[part 11 of 11: package /COM/VECTOR/CFG/WORKFLOW/SYSDESC/SYNC]
AUTOSAR XML (schema 00053)
package /COM/VECTOR/CFG/WORKFLOW/SYSDESC/SYNC  (continued)
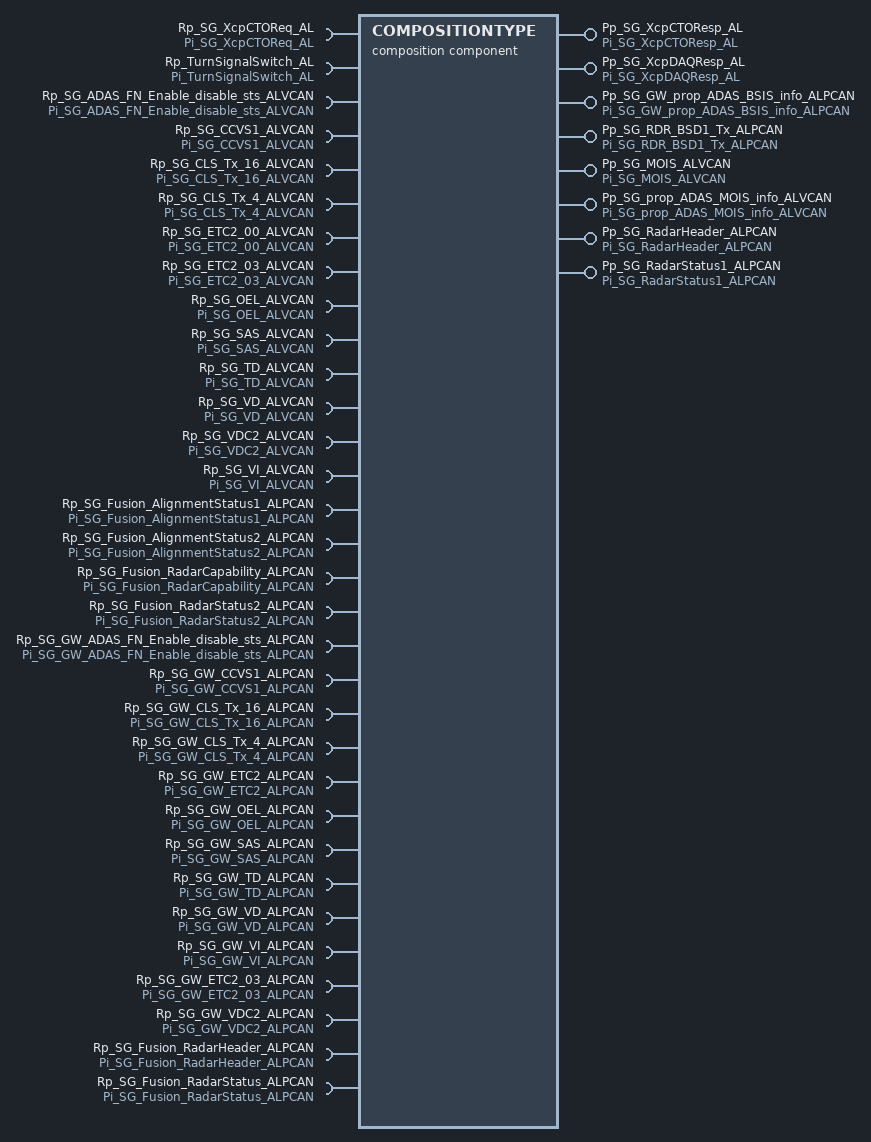
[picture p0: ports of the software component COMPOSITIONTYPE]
  composition sw component type COMPOSITIONTYPE  (continued)
    require port Rp_SG_XcpCTOReq_AL: nonqueued-receiver-com-spec{data-element=Vdp_SG_XcpCTOReq_AL, init-value=fields=[STS_PID:0, STS_XCP_REQ_CTO_Byte1:0, STS_XCP_REQ_CTO_Byte2:0, STS_XCP_REQ_CTO_Byte3:0, STS_XCP_REQ_CTO_Byte4:0, STS_XCP_REQ_CTO_Byte5:0, STS_XCP_REQ_CTO_Byte6:0, STS_XCP_REQ_CTO_Byte7:0, STS_XCP_REQ_CTO_Byte8:0, STS_XCP_REQ_CTO_Byte9:0, STS_XCP_REQ_CTO_Byte10:0, STS_XCP_REQ_CTO_Byte11:0, STS_XCP_REQ_CTO_Byte12:0, STS_XCP_REQ_CTO_Byte13:0, STS_XCP_REQ_CTO_Byte14:0, STS_XCP_REQ_CTO_Byte15:0, STS_XCP_REQ_CTO_Byte16:0, STS_XCP_REQ_CTO_Byte17:0, STS_XCP_REQ_CTO_Byte18:0, STS_XCP_REQ_CTO_Byte19:0, STS_XCP_REQ_CTO_Byte20:0, STS_XCP_REQ_CTO_Byte21:0, STS_XCP_REQ_CTO_Byte22:0, STS_XCP_REQ_CTO_Byte23:0, STS_XCP_REQ_CTO_Byte24:0, STS_XCP_REQ_CTO_Byte25:0, STS_XCP_REQ_CTO_Byte26:0, STS_XCP_REQ_CTO_Byte27:0, STS_XCP_REQ_CTO_Byte28:0, STS_XCP_REQ_CTO_Byte29:0, STS_XCP_REQ_CTO_Byte30:0, STS_XCP_REQ_CTO_Byte31:0, STS_XCP_REQ_CTO_Byte32:0, STS_XCP_REQ_CTO_Byte33:0, STS_XCP_REQ_CTO_Byte34:0, STS_XCP_REQ_CTO_Byte35:0, STS_XCP_REQ_CTO_Byte36:0, STS_XCP_REQ_CTO_Byte37:0, STS_XCP_REQ_CTO_Byte38:0, STS_XCP_REQ_CTO_Byte39:0, STS_XCP_REQ_CTO_Byte40:0, STS_XCP_REQ_CTO_Byte41:0, STS_XCP_REQ_CTO_Byte42:0, STS_XCP_REQ_CTO_Byte43:0, STS_XCP_REQ_CTO_Byte44:0, STS_XCP_REQ_CTO_Byte45:0, STS_XCP_REQ_CTO_Byte46:0, STS_XCP_REQ_CTO_Byte47:0, STS_XCP_REQ_CTO_Byte48:0, STS_XCP_REQ_CTO_Byte49:0, STS_XCP_REQ_CTO_Byte50:0, STS_XCP_REQ_CTO_Byte51:0, STS_XCP_REQ_CTO_Byte52:0, STS_XCP_REQ_CTO_Byte53:0, STS_XCP_REQ_CTO_Byte54:0, STS_XCP_REQ_CTO_Byte55:0, STS_XCP_REQ_CTO_Byte56:0, STS_XCP_REQ_CTO_Byte57:0, STS_XCP_REQ_CTO_Byte58:0, STS_XCP_REQ_CTO_Byte59:0, STS_XCP_REQ_CTO_Byte60:0, STS_XCP_REQ_CTO_Byte61:0, STS_XCP_REQ_CTO_Byte62:0, STS_XCP_REQ_CTO_Byte63:0]}, required-interface=Pi_SG_XcpCTOReq_AL
    provide port Pp_SG_XcpCTOResp_AL: nonqueued-sender-com-spec{data-element=Vdp_SG_XcpCTOResp_AL, init-value=fields=[STS_XCP_RES_CTO_Byte0:0, STS_XCP_RES_CTO_Byte1:0, STS_XCP_RES_CTO_Byte2:0, STS_XCP_RES_CTO_Byte3:0, STS_XCP_RES_CTO_Byte4:0, STS_XCP_RES_CTO_Byte5:0, STS_XCP_RES_CTO_Byte6:0, STS_XCP_RES_CTO_Byte7:0, STS_XCP_RES_CTO_Byte8:0, STS_XCP_RES_CTO_Byte9:0, STS_XCP_RES_CTO_Byte10:0, STS_XCP_RES_CTO_Byte11:0, STS_XCP_RES_CTO_Byte12:0, STS_XCP_RES_CTO_Byte13:0, STS_XCP_RES_CTO_Byte14:0, STS_XCP_RES_CTO_Byte15:0, STS_XCP_RES_CTO_Byte16:0, STS_XCP_RES_CTO_Byte17:0, STS_XCP_RES_CTO_Byte18:0, STS_XCP_RES_CTO_Byte19:0, STS_XCP_RES_CTO_Byte20:0, STS_XCP_RES_CTO_Byte21:0, STS_XCP_RES_CTO_Byte22:0, STS_XCP_RES_CTO_Byte23:0, STS_XCP_RES_CTO_Byte24:0, STS_XCP_RES_CTO_Byte25:0, STS_XCP_RES_CTO_Byte26:0, STS_XCP_RES_CTO_Byte27:0, STS_XCP_RES_CTO_Byte28:0, STS_XCP_RES_CTO_Byte29:0, STS_XCP_RES_CTO_Byte30:0, STS_XCP_RES_CTO_Byte31:0, STS_XCP_RES_CTO_Byte32:0, STS_XCP_RES_CTO_Byte33:0, STS_XCP_RES_CTO_Byte34:0, STS_XCP_RES_CTO_Byte35:0, STS_XCP_RES_CTO_Byte36:0, STS_XCP_RES_CTO_Byte37:0, STS_XCP_RES_CTO_Byte38:0, STS_XCP_RES_CTO_Byte39:0, STS_XCP_RES_CTO_Byte40:0, STS_XCP_RES_CTO_Byte41:0, STS_XCP_RES_CTO_Byte42:0, STS_XCP_RES_CTO_Byte43:0, STS_XCP_RES_CTO_Byte44:0, STS_XCP_RES_CTO_Byte45:0, STS_XCP_RES_CTO_Byte46:0, STS_XCP_RES_CTO_Byte47:0, STS_XCP_RES_CTO_Byte48:0, STS_XCP_RES_CTO_Byte49:0, STS_XCP_RES_CTO_Byte50:0, STS_XCP_RES_CTO_Byte51:0, STS_XCP_RES_CTO_Byte52:0, STS_XCP_RES_CTO_Byte53:0, STS_XCP_RES_CTO_Byte54:0, STS_XCP_RES_CTO_Byte55:0, STS_XCP_RES_CTO_Byte56:0, STS_XCP_RES_CTO_Byte57:0, STS_XCP_RES_CTO_Byte58:0, STS_XCP_RES_CTO_Byte59:0, STS_XCP_RES_CTO_Byte60:0, STS_XCP_RES_CTO_Byte61:0, STS_XCP_RES_CTO_Byte62:0, STS_XCP_RES_CTO_Byte63:0]}, provided-interface=Pi_SG_XcpCTOResp_AL
    provide port Pp_SG_XcpDAQResp_AL: nonqueued-sender-com-spec{data-element=Vdp_SG_XcpDAQResp_AL, init-value=fields=[STS_XCP_RES_DAQ_Byte0:0, STS_XCP_RES_DAQ_Byte1:0, STS_XCP_RES_DAQ_Byte2:0, STS_XCP_RES_DAQ_Byte3:0, STS_XCP_RES_DAQ_Byte4:0, STS_XCP_RES_DAQ_Byte5:0, STS_XCP_RES_DAQ_Byte6:0, STS_XCP_RES_DAQ_Byte7:0, STS_XCP_RES_DAQ_Byte8:0, STS_XCP_RES_DAQ_Byte9:0, STS_XCP_RES_DAQ_Byte10:0, STS_XCP_RES_DAQ_Byte11:0, STS_XCP_RES_DAQ_Byte12:0, STS_XCP_RES_DAQ_Byte13:0, STS_XCP_RES_DAQ_Byte14:0, STS_XCP_RES_DAQ_Byte15:0, STS_XCP_RES_DAQ_Byte16:0, STS_XCP_RES_DAQ_Byte17:0, STS_XCP_RES_DAQ_Byte18:0, STS_XCP_RES_DAQ_Byte19:0, STS_XCP_RES_DAQ_Byte20:0, STS_XCP_RES_DAQ_Byte21:0, STS_XCP_RES_DAQ_Byte22:0, STS_XCP_RES_DAQ_Byte23:0, STS_XCP_RES_DAQ_Byte24:0, STS_XCP_RES_DAQ_Byte25:0, STS_XCP_RES_DAQ_Byte26:0, STS_XCP_RES_DAQ_Byte27:0, STS_XCP_RES_DAQ_Byte28:0, STS_XCP_RES_DAQ_Byte29:0, STS_XCP_RES_DAQ_Byte30:0, STS_XCP_RES_DAQ_Byte31:0, STS_XCP_RES_DAQ_Byte32:0, STS_XCP_RES_DAQ_Byte33:0, STS_XCP_RES_DAQ_Byte34:0, STS_XCP_RES_DAQ_Byte35:0, STS_XCP_RES_DAQ_Byte36:0, STS_XCP_RES_DAQ_Byte37:0, STS_XCP_RES_DAQ_Byte38:0, STS_XCP_RES_DAQ_Byte39:0, STS_XCP_RES_DAQ_Byte40:0, STS_XCP_RES_DAQ_Byte41:0, STS_XCP_RES_DAQ_Byte42:0, STS_XCP_RES_DAQ_Byte43:0, STS_XCP_RES_DAQ_Byte44:0, STS_XCP_RES_DAQ_Byte45:0, STS_XCP_RES_DAQ_Byte46:0, STS_XCP_RES_DAQ_Byte47:0, STS_XCP_RES_DAQ_Byte48:0, STS_XCP_RES_DAQ_Byte49:0, STS_XCP_RES_DAQ_Byte50:0, STS_XCP_RES_DAQ_Byte51:0, STS_XCP_RES_DAQ_Byte52:0, STS_XCP_RES_DAQ_Byte53:0, STS_XCP_RES_DAQ_Byte54:0, STS_XCP_RES_DAQ_Byte55:0, STS_XCP_RES_DAQ_Byte56:0, STS_XCP_RES_DAQ_Byte57:0, STS_XCP_RES_DAQ_Byte58:0, STS_XCP_RES_DAQ_Byte59:0, STS_XCP_RES_DAQ_Byte60:0, STS_XCP_RES_DAQ_Byte61:0, STS_XCP_RES_DAQ_Byte62:0, STS_XCP_RES_DAQ_Byte63:0]}, provided-interface=Pi_SG_XcpDAQResp_AL
    29 x require port:
      Rp_TurnSignalSwitch_AL: nonqueued-receiver-com-spec{data-element=Vdp_TurnSignalSwitch_AL, init-value=0}, required-interface=Pi_TurnSignalSwitch_AL
      Rp_SG_ADAS_FN_Enable_disable_sts_ALVCAN: nonqueued-receiver-com-spec{data-element=Vdp_SG_ADAS_FN_Enable_disable_sts_ALVCAN, init-value=fields=[BSIS_Fn_Switch_Sts:0, MessageAliveCounter:0, MessageCRC:0, MOIS_Fn_Switch_sts:0]}, required-interface=Pi_SG_ADAS_FN_Enable_disable_sts_ALVCAN
      Rp_SG_CCVS1_ALVCAN: nonqueued-receiver-com-spec{data-element=Vdp_SG_CCVS1_ALVCAN, init-value=fields=[BrakeSwitch:0, ParkingBrakeSwitch:0, WheelBasedVehicleSpeed:0]}, required-interface=Pi_SG_CCVS1_ALVCAN
      Rp_SG_CLS_Tx_16_ALVCAN: nonqueued-receiver-com-spec{data-element=Vdp_SG_CLS_Tx_16_ALVCAN, init-value=fields=[Crawler_confi_status_info:0, Transmission_type_info:0]}, required-interface=Pi_SG_CLS_Tx_16_ALVCAN
      Rp_SG_CLS_Tx_4_ALVCAN: nonqueued-receiver-com-spec{data-element=Vdp_SG_CLS_Tx_4_ALVCAN, init-value=fields=[Ignition:0, ReverseSwitchInfo:0]}, required-interface=Pi_SG_CLS_Tx_4_ALVCAN
      Rp_SG_ETC2_00_ALVCAN: nonqueued-receiver-com-spec{data-element=Vdp_SG_ETC2_00_ALVCAN, init-value=fields=TransCurrentGear_00:125}, required-interface=Pi_SG_ETC2_00_ALVCAN
      Rp_SG_ETC2_03_ALVCAN: nonqueued-receiver-com-spec{data-element=Vdp_SG_ETC2_03_ALVCAN, init-value=fields=TransCurrentGear_03:0}, required-interface=Pi_SG_ETC2_03_ALVCAN
      Rp_SG_OEL_ALVCAN: nonqueued-receiver-com-spec{data-element=Vdp_SG_OEL_ALVCAN, init-value=fields=[HazardLightSwitch:0, HighLowBeamSwitch:0, TurnSignalSwitch:0]}, required-interface=Pi_SG_OEL_ALVCAN
      Rp_SG_SAS_ALVCAN: nonqueued-receiver-com-spec{data-element=Vdp_SG_SAS_ALVCAN, init-value=fields=[ActiveMode:0, Calibrated:0, MessageChecksum:0, MessageCounter:0, SteeringWheelAngle:0, SteeringWheelAngleRange:0, SteeringWheelAngleRangeCounter:0, SteeringWheelAngleRangeCounterType:0]}, required-interface=Pi_SG_SAS_ALVCAN
      Rp_SG_TD_ALVCAN: nonqueued-receiver-com-spec{data-element=Vdp_SG_TD_ALVCAN, init-value=fields=[Day:0, Hours:0, LocalHourOffset:125, LocalMinuteOffset:125, Minutes:0, Month:0, Seconds:0, Year:0]}, required-interface=Pi_SG_TD_ALVCAN
      Rp_SG_VD_ALVCAN: nonqueued-receiver-com-spec{data-element=Vdp_SG_VD_ALVCAN, init-value=fields=Total_vehicle_distance:0}, required-interface=Pi_SG_VD_ALVCAN
      Rp_SG_VDC2_ALVCAN: nonqueued-receiver-com-spec{data-element=Vdp_SG_VDC2_ALVCAN, init-value=fields=[LateralAcceleration:32127, LongitudinalAcceleration:125, SteerWheelAngle:32127, YawRate:32113]}, required-interface=Pi_SG_VDC2_ALVCAN
      Rp_SG_VI_ALVCAN: nonqueued-receiver-com-spec{data-element=Vdp_SG_VI_ALVCAN, init-value=fields=VehicleIdentification:0}, required-interface=Pi_SG_VI_ALVCAN
      Rp_SG_Fusion_AlignmentStatus1_ALPCAN: nonqueued-receiver-com-spec{data-element=Vdp_SG_Fusion_AlignmentStatus1_ALPCAN, init-value=fields=[AL_STS_001_CYCLE_COUNTER_Rx:0, AL_STS_001_MH_CRC16_Rx:0, STS_AAAzimuthStd_Rx:0, STS_AACurrentAzimuth_Rx:0, STS_AACurrentElevation_Rx:0, STS_AACurrentRoll_Rx:0, STS_AAElevationStd_Rx:0, STS_AARoll_Std_Rx:0, STS_AlignmentAutoStatus_Rx:0, STS_AlignmentAzimuth_Rx:0, STS_AlignmentElevation_Rx:0, STS_AlignmentError_Rx:0, STS_AlignmentModeIn_Rx:0, STS_AlignmentModeOut_Rx:0, STS_AutoAlignmentFailRootCause_Rx:0, STS_AzimuthErrorNegative_Rx:0, STS_AzimuthErrorPositive_Rx:0, STS_AzimuthStd_Rx:0, STS_AzimuthUpdates_Rx:0, STS_CalDisplay_Rx:0, STS_CalTime_Rx:0, STS_CoordinateSystemInput_Rx:0, STS_ElevationErrorNegative_Rx:0, STS_ElevationErrorPositive_Rx:0, STS_ElevationStd_Rx:0, STS_ElevationUpdates_Rx:0, STS_HostSpdCompensationFactorQF_Rx:0, STS_HostSpeedCompensationFactor_Rx:0, 0, 0, 0, 0, 0, 0, STS_ProgressPercent_Rx:0, STS_RadarTypeInput_Rx:0, STS_Roll_Updates_Rx:0, STS_RollErrorNegative_Rx:0, STS_RollErrorPositive_Rx:0, STS_StartAzimuth_Rx:0, STS_StartElevation_Rx:0, STS_StartRoll_Rx:0]}, required-interface=Pi_SG_Fusion_AlignmentStatus1_ALPCAN
      Rp_SG_Fusion_AlignmentStatus2_ALPCAN: nonqueued-receiver-com-spec{data-element=Vdp_SG_Fusion_AlignmentStatus2_ALPCAN, init-value=fields=[AL_STS_002_CYCLE_COUNTER_Rx:0, AL_STS_002_MH_CRC16_Rx:0, STS_AlignmentServiceStatus_Rx:0, STS_AlignmentShortTrackStatus_Rx:0, STS_AlignmentStaticStatus_Rx:0, STS_AverageNumberOfDetections_Rx:0, STS_AverageSpeed_Rx:0, STS_DistanceAbsolute_Rx:0, STS_DistanceEffective_Rx:0, STS_DurationAbsolute_Rx:0, STS_DurationEffective_Rx:0, STS_ImpactByInterference_Rx:0, STS_Measured_Range_Rx:0, STS_MeasuredAmpSTD_Rx:0, STS_MeasuredRangeRate_Rx:0, STS_MeasuredRangeRateStd_Rx:0, STS_MeasuredRangeStd_Rx:0, STS_MeasuredRawAmplitude_Rx:0, STS_VehicleCondition_Rx:0]}, required-interface=Pi_SG_Fusion_AlignmentStatus2_ALPCAN
      Rp_SG_Fusion_RadarCapability_ALPCAN: nonqueued-receiver-com-spec{data-element=Vdp_SG_Fusion_RadarCapability_ALPCAN, init-value=fields=[CAP_AngleAzimuthRangeEnd_Rx:0, CAP_AngleAzimuthRangeStart_Rx:0, CAP_BlockageActive_Rx:0, CAP_BlockageProbability_Rx:0, CAP_BlockageSensitivity_Rx:0, CAP_BlockageStatus_Rx:0, CAP_BlockageValue_Rx:0, CAP_CYCLE_COUNTER_Rx:0, CAP_DampingActive_Rx:0, CAP_DampingCurrent_Rx:0, CAP_DampingStandardDeviation_Rx:0, CAP_DampingStatus_Rx:0, CAP_FreeSightCheckActive_Rx:0, CAP_FreeSightCheckStatus_Rx:0, CAP_MaxDetectionRangeCar_0_Rx:0, CAP_MaxDetectionRangeCar_1_Rx:0, CAP_MaxDetectionRangeCar_2_Rx:0, CAP_MaxDetRangeMotorbike_0_Rx:0, CAP_MaxDetRangeMotorbike_1_Rx:0, CAP_MaxDetRangeMotorbike_2_Rx:0, CAP_MaxDetRangePedestrian_0_Rx:0, CAP_MaxDetRangePedestrian_1_Rx:0, CAP_MaxDetRangePedestrian_2_Rx:0, CAP_MH_CRC16_Rx:0, CAP_RangeEstimationActive_Rx:0, CAP_RangeEstimationStatus_Rx:0, CAP_SideLobeLevelBeamformer_Rx:0, CAP_SLBlockageFilterValue_Rx:0, CAP_SLBlockageFlag_Rx:0, CAP_SLLMonitoringActive_Rx:0, CAP_SLLMonitoringStatus_Rx:0]}, required-interface=Pi_SG_Fusion_RadarCapability_ALPCAN
      Rp_SG_Fusion_RadarStatus2_ALPCAN: nonqueued-receiver-com-spec{data-element=Vdp_SG_Fusion_RadarStatus2_ALPCAN, init-value=fields=[STS_AF_CORE_THROUGHPUT_Rx:0, STS_BRR_STATUS_Rx:0, STS_CAN_NM_State_Rx:0, STS_CORE_ACTV_FLT_BYTE_0_to_3_Rx:0, STS_CORE_ACTV_FLT_BYTE_4_to_7_Rx:0, STS_CORE_ACTV_FLT_BYTE_8_to_11_Rx:0, STS_CORE_ACTV_FLT_BYTE_11_to_15_Rx:0, STS_First_CAN_Det_Inst_Latency_Rx:0, STS_Gear_Position_Rx:0, STS_INTRFC_VERSION_ID_MAJOR_Rx:0, STS_INTRFC_VERSION_ID_MINOR_Rx:0, STS_INTRFC_VERSION_ID_PATCH_Rx:0, STS_Last_CAN_Det_Inst_Latency_Rx:0, STS_MCU_TEMP_Rx:0, STS_MH_002_CRC16_Rx:0, STS_MH_002_CYCLE_COUNTER_Rx:0, 0, STS_MMIC_TEMP_RX_Rx:0, STS_MMIC_TEMP_TX0_Rx:0, STS_MMIC_TEMP_TX1_2_Rx:0, STS_MMIC_TEMP_TX3_4_Rx:0, STS_NO_TSYN_ERROR_Rx:0, STS_POINT_OF_TRIGGER_Rx:0, STS_RAIN_COUNT_Rx:0, STS_RDD_CORE_THROUGHPUT_Rx:0, STS_SCAN_TYPE_Rx:0, STS_STEERING_ANGLE_Rx:0, STS_STEERING_ANGLE_SIGN_Rx:0, STS_TIME_SYNC_OFFSET_Rx:0, STS_TKEY_ACTV_FLT_BYTE_0_to_3_Rx:0, STS_TKEY_ACTV_FLT_BYTE_4_to_5_Rx:0, STS_VEH_SPEED_DIRECTION_Rx:0, STS_Vehicle_Speed_Calc_QF_Rx:0, STS_VEHICLE_SPEED_CALC_Rx:0, STS_VEHICLE_SUPPLY_VOLTAGE_Rx:0, STS_XCVR_OPERATIONAL_Rx:0, STS_YAW_RATE_BIAS_Rx:0, STS_Yaw_Rate_Calc_QF_Rx:0]}, required-interface=Pi_SG_Fusion_RadarStatus2_ALPCAN
      Rp_SG_GW_ADAS_FN_Enable_disable_sts_ALPCAN: nonqueued-receiver-com-spec{data-element=Vdp_SG_GW_ADAS_FN_Enable_disable_sts_ALPCAN, init-value=fields=[AEBS_FN_Switch_sts:0, BSIS_fn_Switch_Sts:0, DDAW_fn_switch_sts:0, DDAW_warning_suppression:0, LDWS_FN_Switch_sts:0, MessageAliveCounter:0, MessageCRC:0, MOIS_Fn_Switch_sts:0]}, required-interface=Pi_SG_GW_ADAS_FN_Enable_disable_sts_ALPCAN
      Rp_SG_GW_CCVS1_ALPCAN: nonqueued-receiver-com-spec{data-element=Vdp_SG_GW_CCVS1_ALPCAN, init-value=fields=[BrakeSwitch:0, ParkingBrakeSwitch:0, WheelBasedVehicleSpeed:0]}, required-interface=Pi_SG_GW_CCVS1_ALPCAN
      Rp_SG_GW_CLS_Tx_16_ALPCAN: nonqueued-receiver-com-spec{data-element=Vdp_SG_GW_CLS_Tx_16_ALPCAN, init-value=fields=[Crawler_confi_status_info:0, Transmission_type_info:0]}, required-interface=Pi_SG_GW_CLS_Tx_16_ALPCAN
      Rp_SG_GW_CLS_Tx_4_ALPCAN: nonqueued-receiver-com-spec{data-element=Vdp_SG_GW_CLS_Tx_4_ALPCAN, init-value=fields=[Ignition:0, ReverseSwitchInfo:0]}, required-interface=Pi_SG_GW_CLS_Tx_4_ALPCAN
      Rp_SG_GW_ETC2_ALPCAN: nonqueued-receiver-com-spec{data-element=Vdp_SG_GW_ETC2_ALPCAN, init-value=fields=TransCurrentGear_00:0}, required-interface=Pi_SG_GW_ETC2_ALPCAN
      Rp_SG_GW_OEL_ALPCAN: nonqueued-receiver-com-spec{data-element=Vdp_SG_GW_OEL_ALPCAN, init-value=fields=[HazardLightSwitch:0, HighLowBeamSwitch:0, TurnSignalSwitch:0]}, required-interface=Pi_SG_GW_OEL_ALPCAN
      Rp_SG_GW_SAS_ALPCAN: nonqueued-receiver-com-spec{data-element=Vdp_SG_GW_SAS_ALPCAN, init-value=fields=[MessageChecksum:0, MessageCounter:0, SteerAngleSensorActiveMode:0, SteerAngleSensorCalibrated:0, SteerWheelAngle:0, SteerWheelAngleRange:0, SteerWheelAngleRangeCounter:0, SteerWheelAngleRangeCounterType:0]}, required-interface=Pi_SG_GW_SAS_ALPCAN
      Rp_SG_GW_TD_ALPCAN: nonqueued-receiver-com-spec{data-element=Vdp_SG_GW_TD_ALPCAN, init-value=fields=[Day:0, Hours:0, LocalHourOffset:0, LocalMinuteOffset:0, Minutes:0, Month:0, Seconds:0, Year:0]}, required-interface=Pi_SG_GW_TD_ALPCAN
      Rp_SG_GW_VD_ALPCAN: nonqueued-receiver-com-spec{data-element=Vdp_SG_GW_VD_ALPCAN, init-value=fields=TotalVehicleDistance:0}, required-interface=Pi_SG_GW_VD_ALPCAN
      Rp_SG_GW_VI_ALPCAN: nonqueued-receiver-com-spec{data-element=Vdp_SG_GW_VI_ALPCAN, init-value=fields=VehicleIdentification:0}, required-interface=Pi_SG_GW_VI_ALPCAN
      Rp_SG_GW_ETC2_03_ALPCAN: nonqueued-receiver-com-spec{data-element=Vdp_SG_GW_ETC2_03_ALPCAN, init-value=fields=TransCurrentGear_03:0}, required-interface=Pi_SG_GW_ETC2_03_ALPCAN
      Rp_SG_GW_VDC2_ALPCAN: nonqueued-receiver-com-spec{data-element=Vdp_SG_GW_VDC2_ALPCAN, init-value=fields=[LateralAcceleration:0, LongitudinalAcceleration:0, SteerWheelAngle:0, YawRate:0]}, required-interface=Pi_SG_GW_VDC2_ALPCAN
    4 x provide port:
      Pp_SG_GW_prop_ADAS_BSIS_info_ALPCAN: nonqueued-sender-com-spec{data-element=Vdp_SG_GW_prop_ADAS_BSIS_info_ALPCAN, init-value=fields=[BlindSpotCollisionWarningLevel:0, BlindSpotDetectionState:0]}, provided-interface=Pi_SG_GW_prop_ADAS_BSIS_info_ALPCAN
      Pp_SG_RDR_BSD1_Tx_ALPCAN: nonqueued-sender-com-spec{data-element=Vdp_SG_RDR_BSD1_Tx_ALPCAN, init-value=fields=[BlindSpotCollisionWarningLevel_Tx:0, BlindSpotDetectionState_Tx:0]}, provided-interface=Pi_SG_RDR_BSD1_Tx_ALPCAN
      Pp_SG_MOIS_ALVCAN: nonqueued-sender-com-spec{data-element=Vdp_SG_MOIS_ALVCAN, init-value=fields=[MOISCollisionWarningLevel:0, MovingObjectDetectionState:0]}, provided-interface=Pi_SG_MOIS_ALVCAN
      Pp_SG_prop_ADAS_MOIS_info_ALVCAN: nonqueued-sender-com-spec{data-element=Vdp_SG_prop_ADAS_MOIS_info_ALVCAN, init-value=fields=[rdn_MOISCollisionWarningLevel:0, rdn_MovingObjectDetectionState:0]}, provided-interface=Pi_SG_prop_ADAS_MOIS_info_ALVCAN
    require port Rp_SG_Fusion_RadarHeader_ALPCAN: nonqueued-receiver-com-spec{data-element=Vdp_SG_Fusion_RadarHeader_ALPCAN, init-value=fields=[HED_ALIGN_HOR_REF_Rx:0, HED_ALIGN_VER_REF_Rx:0, HED_Auth_CRC32_Rx:0, HED_DATA_QUALIFIER_Rx:0, HED_DET_BI_STATIC_COUNT_Rx:0, HED_DET_NUM_OF_1PASS_Rx:0, HED_DET_NUM_OF_2PASS_Rx:0, HED_DET_RANGE_MAX_Rx:0, HED_DET_RANGE_MIN_Rx:0, HED_DET_SPEED_RANGE_MAX_Rx:0, HED_DET_SPEED_RANGE_MIN_Rx:0, HED_FOV_HOR_MAX_Rx:0, HED_FOV_HOR_MIN_Rx:0, HED_FOV_VER_MAX_Rx:0, HED_FOV_VER_MIN_Rx:0, HED_LOOK_ID_Rx:0, HED_LOOK_INDEX_Rx:0, HED_MAX_NUM_OF_DETECTIONS_Rx:0, HED_MH_CRC16_Rx:0, HED_MH_CYCLE_COUNTER_Rx:0, HED_NUM_OF_RESTBINS_USED_Rx:0, HED_NUM_OF_VALID_DETECTIONS_Rx:0, HED_OPERATION_MODE_Rx:0, HED_PROCESSED_RANGE_Rx:0, HED_R_WRAPPING_Rx:5 x 0, HED_Rain_Level_Rx:7 x 0, HED_RDR_HEADER_CMAC_Rx:5 x 0, HED_RDR_HEADER_FV_Rx:7 x 0, HED_SCAN_INDEX_Rx:0, HED_SENSOR_TIME_STAMP_NS_Rx:0, HED_SENSOR_TIME_STAMP_SEC_Rx:0, HED_SLOPE_CORR_EXECUTIONFLAG_Rx:0, HED_TIME_SYNC_SRC_MASTER_Rx:0, HED_TIME_SYNC_VALIDITY_FLAG_Rx:0, HED_TRIGGER_TIME_Rx:0, HED_V_WRAPPING_Rx:0]}, required-interface=Pi_SG_Fusion_RadarHeader_ALPCAN
    require port Rp_SG_Fusion_RadarStatus_ALPCAN: nonqueued-receiver-com-spec{data-element=Vdp_SG_Fusion_RadarStatus_ALPCAN, init-value=fields=[STS_AF_TIME_INST_Rx:0, STS_AF_TIME_PEAK_Rx:0, STS_DET_DBC_BASE_VER_MAJOR_Rx:0, STS_DET_DBC_BASE_VER_MINOR_Rx:0, STS_DIST_FRNT_BMPR_TO_RR_AXL_Rx:0, STS_HARDWARE_VERSION_Rx:0, STS_MAIN_CORE_TIME_INST_Rx:0, STS_MAIN_CORE_TIME_PEAK_Rx:0, STS_MH_001_CRC16_Rx:0, STS_MH_001_CYCLE_COUNTER_Rx:0, STS_PBL_VERSION_FIELD1_Rx:0, STS_PBL_VERSION_FIELD2_Rx:0, STS_PBL_VERSION_FIELD3_Rx:0, STS_PBL_VERSION_FIELD4_Rx:0, STS_PCAN_PROTOCOL_VER_MAJOR_Rx:0, STS_PCAN_PROTOCOL_VER_MINOR_Rx:0, STS_PLATFORM_VARIANT_Rx:0, STS_RDD_CORE_TIME_INST_Rx:0, STS_RDD_CORE_TIME_PEAK_Rx:0, STS_SENSOR_HEIGHT_Rx:0, STS_SENSOR_MOUNT_ORNT_PITCH_Rx:0, STS_SENSOR_MOUNT_ORNT_ROLL_Rx:0, STS_SENSOR_MOUNT_ORNT_YAW_Rx:0, STS_SENSOR_MOUNT_POS_X_Rx:0, STS_SENSOR_MOUNT_POS_Y_Rx:0, STS_SENSOR_MOUNT_POS_Z_Rx:0, STS_SENSOR_POLARITY_Rx:0, STS_SENSOR_POSITION_Rx:0, STS_SERIAL_NUM_JULIAN_DAY_Rx:0, STS_SERIAL_NUM_JULIAN_YEAR_Rx:0, STS_SERIAL_NUMBER_SEQUENCE_Rx:0, STS_SMC_CAL_VER_MAJOR_Rx:0, STS_SMC_CAL_VER_MINOR_Rx:0, STS_SMC_PLATFROM_VERSION_Rx:0, STS_SMC_SECTION_COMPTBLITY_Rx:0, STS_SP_CORE_TIME_INST_Rx:0, STS_SP_CORE_TIME_PEAK_Rx:0, STS_SW_VERSION_FIELD1_Rx:0, STS_SW_VERSION_FIELD2_Rx:0, STS_SW_VERSION_FIELD3_Rx:0, STS_SW_VERSION_FIELD4_Rx:0, STS_TIME_SINCE_POWER_ON_Rx:0, STS_USC_CAL_VER_MAJOR_Rx:0, STS_USC_CAL_VER_MINOR_Rx:0, STS_USC_SECTION_COMPTBLITY_Rx:0, STS_VIN_Status_Rx:0]}, required-interface=Pi_SG_Fusion_RadarStatus_ALPCAN
    provide port Pp_SG_RadarHeader_ALPCAN: nonqueued-sender-com-spec{data-element=Vdp_SG_RadarHeader_ALPCAN, init-value=fields=[HED_ALIGN_HOR_REF:0, HED_ALIGN_VER_REF:0, HED_Auth_CRC32:0, HED_DATA_QUALIFIER:1, HED_DET_BI_STATIC_COUNT:0, HED_DET_NUM_OF_1PASS:0, HED_DET_NUM_OF_2PASS:0, HED_DET_RANGE_MAX:0, HED_DET_RANGE_MIN:0, HED_DET_SPEED_RANGE_MAX:32768, HED_DET_SPEED_RANGE_MIN:32768, HED_FOV_HOR_MAX:0, HED_FOV_HOR_MIN:128, HED_FOV_VER_MAX:0, HED_FOV_VER_MIN:0, HED_LOOK_ID:0, HED_LOOK_INDEX:0, HED_MAX_NUM_OF_DETECTIONS:0, HED_MH_CRC16:0, HED_MH_CYCLE_COUNTER:0, HED_NUM_OF_RESTBINS_USED:0, HED_NUM_OF_VALID_DETECTIONS:0, HED_OPERATION_MODE:0, HED_PROCESSED_RANGE:0, HED_R_WRAPPING:5 x 90, HED_Rain_Level:7 x 0, HED_RDR_HEADER_CMAC:5 x 0, HED_RDR_HEADER_FV:7 x 0, HED_SCAN_INDEX:0, HED_SENSOR_TIME_STAMP_NS:0, HED_SENSOR_TIME_STAMP_SEC:0, HED_SLOPE_CORR_EXECUTIONFLAG:0, HED_TIME_SYNC_SRC_MASTER:0, HED_TIME_SYNC_VALIDITY_FLAG:0, HED_TRIGGER_TIME:0, HED_V_WRAPPING:0]}, provided-interface=Pi_SG_RadarHeader_ALPCAN
    provide port Pp_SG_RadarStatus1_ALPCAN: nonqueued-sender-com-spec{data-element=Vdp_SG_RadarStatus1_ALPCAN, init-value=fields=[STS_AF_TIME_INST:0, STS_AF_TIME_PEAK:0, STS_DET_DBC_BASE_VER_MAJOR:0, STS_DET_DBC_BASE_VER_MINOR:0, STS_DIST_FRNT_BMPR_TO_RR_AXL:0, STS_HARDWARE_VERSION:0, STS_MAIN_CORE_TIME_INST:0, STS_MAIN_CORE_TIME_PEAK:0, STS_MH_001_CRC16:0, STS_MH_001_CYCLE_COUNTER:0, STS_PBL_VERSION_FIELD1:0, STS_PBL_VERSION_FIELD2:0, STS_PBL_VERSION_FIELD3:0, STS_PBL_VERSION_FIELD4:0, STS_PCAN_PROTOCOL_VER_MAJOR:0, STS_PCAN_PROTOCOL_VER_MINOR:0, STS_PLATFORM_VARIANT:0, STS_RDD_CORE_TIME_INST:0, STS_RDD_CORE_TIME_PEAK:0, STS_SENSOR_HEIGHT:0, STS_SENSOR_MOUNT_ORNT_PITCH:0, STS_SENSOR_MOUNT_ORNT_ROLL:0, STS_SENSOR_MOUNT_ORNT_YAW:0, STS_SENSOR_MOUNT_POS_X:8192, STS_SENSOR_MOUNT_POS_Y:32768, STS_SENSOR_MOUNT_POS_Z:32768, STS_SENSOR_POLARITY:0, STS_SENSOR_POSITION:0, STS_SERIAL_NUM_JULIAN_DAY:365, STS_SERIAL_NUM_JULIAN_YEAR:0, STS_SERIAL_NUMBER_SEQUENCE:1234, STS_SMC_CAL_VER_MAJOR:0, STS_SMC_CAL_VER_MINOR:0, STS_SMC_PLATFROM_VERSION:0, STS_SMC_SECTION_COMPTBLITY:0, STS_SP_CORE_TIME_INST:0, STS_SP_CORE_TIME_PEAK:0, STS_SW_VERSION_FIELD1:0, STS_SW_VERSION_FIELD2:0, STS_SW_VERSION_FIELD3:0, STS_SW_VERSION_FIELD4:0, STS_TIME_SINCE_POWER_ON:0, STS_USC_CAL_VER_MAJOR:0, STS_USC_CAL_VER_MINOR:0, STS_USC_SECTION_COMPTBLITY:0, STS_VIN_Status:0]}, provided-interface=Pi_SG_RadarStatus1_ALPCAN
    41 x component:
      Det: type=Det
      ComM: type=ComM
      EcuM: type=EcuM
      BswM: type=BswM
      Os_OsCore0_swc: type=Os_OsCore0_swc
      SWC_PLT_CDD_Logging: type=SWC_PLT_CDD_Logging
      SWC_PLT_CDD_Radar_Control: type=SWC_PLT_CDD_Radar_Control
      SWC_PLT_CDD_XCP: type=SWC_PLT_CDD_XCP
      StbM: type=StbM
      SWC_PLT_CDD_ECUSync: type=SWC_PLT_CDD_ECUSync
      SWC_PLT_Appl_Communication: type=SWC_PLT_Appl_Communication
      SWC_PLT_Radar_Alignment_Handler: type=SWC_PLT_Radar_Alignment_Handler
      SWC_PLT_Appl_PlatformTime: type=SWC_PLT_Appl_PlatformTime
      SWC_PLT_Appl_RTM: type=SWC_PLT_Appl_RTM
      SWC_CDD_IPC: type=SWC_CDD_IPC
      SWC_PLT_CDD_FailSafe: type=SWC_PLT_CDD_FailSafe
      SWC_PLT_Appl_FaultMgr: type=SWC_PLT_Appl_FaultMgr
      SWC_PLT_CDD_MCU_Safety: type=SWC_PLT_CDD_MCU_Safety
      SWC_PLT_Appl_Diag: type=SWC_PLT_Appl_Diag
      SWC_PLT_Appl_ModeManager: type=SWC_PLT_Appl_ModeManager
      SWC_PLT_Appl_IoHwAb: type=SWC_PLT_Appl_IoHwAb
      SWC_PLT_Service_IoHwAb: type=SWC_PLT_Service_IoHwAb
      NvM: type=NvM
      SWC_PLT_Appl_NvMHandler: type=SWC_PLT_Appl_NvMHandler
      SWC_PLT_CDD_ExternalWdg: type=SWC_PLT_CDD_ExternalWdg
      SWC_PLT_Appl_IntWDG: type=SWC_PLT_Appl_IntWDG
      SWC_PLT_CDD_WdgHandler: type=SWC_PLT_CDD_WdgHandler
      SWC_Appl_Project: type=SWC_Appl_Project
      SWC_PLT_CDD_FCRU: type=SWC_PLT_CDD_FCRU
      SWC_PLT_CDD_HIL: type=SWC_PLT_CDD_HIL
      SWC_PRJ_Appl_FaultMgr: type=SWC_PRJ_Appl_FaultMgr
      SWC_PLT_CDD_TimeSync: type=SWC_PLT_CDD_TimeSync
      Csm: type=Csm
      SWC_PRJ_Appl_Power_Manager: type=SWC_PRJ_Appl_Power_Manager
      Dcm: type=Dcm
      SWC_CMP_PRJ_UDSHandler: type=SWC_CMP_PRJ_UDSHandler
      WdgM_OsCore0_ASIL: type=WdgM_OsCore0_ASIL
      DemMaster_Invalid_OsApplication: type=DemMaster_Invalid_OsApplication
      DemSatellite_Invalid_OsApplication: type=DemSatellite_Invalid_OsApplication
      SWC_PRJ_Appl_SensorPosition: type=SWC_PRJ_Appl_SensorPosition
      SWC_PRJ_Appl_Security_Manager: type=SWC_PRJ_Appl_Security_Manager
    connect SWC_PLT_CDD_Logging.PostRadarProcessing_Debug -> SWC_PLT_CDD_Radar_Control.PostRadarProcessing_Debug  # UB:Derived from original system description
    connect SWC_PLT_CDD_Logging.PostRadarProcessing_Detection -> SWC_PLT_CDD_Radar_Control.PostRadarProcessing_Detection  # UB:Derived from original system description
    connect SWC_PLT_CDD_Logging.PostRadarProcessing_Header -> SWC_PLT_CDD_Radar_Control.PostRadarProcessing_Header  # UB:Derived from original system description
    connect SWC_PLT_CDD_Logging.PostRadarProcessing_MMIC -> SWC_PLT_CDD_Radar_Control.PostRadarProcessing_MMIC  # UB:Derived from original system description
    connect SWC_PLT_CDD_Logging.PostRadarProcessing_Radar_Capability -> SWC_PLT_CDD_Radar_Control.PostRadarProcessing_Radar_Capability  # UB:Derived from original system description
    connect SWC_PLT_CDD_Logging.PostRadarProcessing_RDD -> SWC_PLT_CDD_Radar_Control.PostRadarProcessing_RDD  # UB:Derived from original system description
    connect SWC_PLT_CDD_Logging.PostRadarProcessing_Status -> SWC_PLT_CDD_Radar_Control.PostRadarProcessing_Status  # UB:Derived from original system description
    connect SWC_PLT_CDD_Logging.PostRadarProcessing_ADC -> SWC_PLT_CDD_Radar_Control.PostRadarProcessing_ADC  # UB:Derived from original system description
    connect SWC_PLT_CDD_ECUSync.Pp_Time_Stamp_Delta -> SWC_PLT_CDD_Logging.Rp_Time_Stamp_Delta  # UB:Derived from original system description
    connect SWC_PLT_CDD_ECUSync.Pp_TimeSync_Status_No_Tsyn_Error -> SWC_PLT_CDD_Logging.Rp_TimeSync_Status_No_Tsyn_Error  # UB:Derived from original system description
    connect SWC_PLT_CDD_ECUSync.Pp_EcuSync_Offset_ms -> SWC_PLT_CDD_Logging.Rp_EcuSync_Offset_ms
    connect StbM.GlobalTime_StatusEvent_StbMSynchronizedTimeBase -> SWC_PLT_CDD_ECUSync.Rp_StbMStatusNotificationCallback_StbMSynchronizedTimeBase
    connect StbM.GlobalTime_Slave_StbMSynchronizedTimeBase -> SWC_PLT_CDD_ECUSync.Pp_GlobalTime_Slave_StbMSynchronizedTimeBase
    connect SWC_PLT_CDD_Radar_Control.Pp_Radar_Ctl_Look_Trigger -> SWC_PLT_CDD_ECUSync.Pp_Radar_Ctl_Look_Trigger  # UB:Derived from original system description
    connect SWC_PLT_CDD_ECUSync.Pp_Radar_Ctl_Look_Complete -> SWC_PLT_CDD_Radar_Control.Rp_Radar_Ctl_Look_Complete  # UB:Derived from original system description
    delegate SWC_PLT_Appl_Communication.Pp_SG_TrackerObject004 <-> outer port Pp_SG_TrackerObject004  # UB:Derived from original system description
    connect SWC_PLT_CDD_Logging.StbM_MeasurementNotification_StbMSynchronizedTimeBase -> StbM.StbM_MeasurementNotification_StbMSynchronizedTimeBase
    connect SWC_PLT_CDD_XCP.Pp_XCP_CW_Mode -> SWC_PLT_CDD_Radar_Control.Rp_XCP_CW_Mode  # UB:Derived from original system description
    connect SWC_PLT_CDD_XCP.Pp_XCP_Op_Mode -> SWC_PLT_CDD_Radar_Control.Rp_XCP_Op_Mode  # UB:Derived from original system description
    connect SWC_PLT_CDD_XCP.Pp_XCP_Single_Look_Enable -> SWC_PLT_CDD_Radar_Control.Rp_XCP_Single_Look_Enable  # UB:Derived from original system description
    connect SWC_PLT_Appl_Diag.Pp_DTC_Status -> SWC_PLT_Appl_FaultMgr.Rp_DTC_Status  # UB:Derived from original system description
    connect SWC_PLT_Appl_Diag.Pp_MCU_Startup_Fault_Status -> SWC_PLT_Appl_FaultMgr.Rp_MCU_Startup_Fault_Status  # UB:Derived from original system description
    connect SWC_PLT_Appl_Diag.Pp_MicroTemp_Low_Deb_Reset -> SWC_PLT_Appl_FaultMgr.Rp_MicroTemp_Low_Deb_Reset  # UB:Derived from original system description
    connect SWC_PLT_Appl_Diag.Pp_Platform_Battery_Tst -> SWC_PLT_Appl_FaultMgr.Rp_Platform_Battery_Tst  # UB:Derived from original system description
    connect SWC_PLT_Appl_Diag.Pp_PltToFltMgr_Can_Bus_Off_Fault_Status -> SWC_PLT_Appl_FaultMgr.Rp_PltToFltMgr_Can_Bus_Off_Fault_Status  # UB:Derived from original system description
    connect SWC_PLT_Appl_Diag.Pp_PltToFltMgr_Can_Controller_Fault_Status -> SWC_PLT_Appl_FaultMgr.Rp_PltToFltMgr_Can_Controller_Fault_Status  # UB:Derived from original system description
    connect SWC_PLT_Appl_Diag.Pp_PltToFltMgr_Host_Micro_Diag -> SWC_PLT_Appl_FaultMgr.Rp_PltToFltMgr_Host_Micro_Diag  # UB:Derived from original system description
    connect SWC_PLT_Appl_Diag.Pp_PltToFltMgr_Micro_Temp_Fault_Status -> SWC_PLT_Appl_FaultMgr.Rp_PltToFltMgr_Micro_Temp_Fault_Status  # UB:Derived from original system description
    connect SWC_PLT_Appl_Diag.Pp_PltToFltMgr_Mirror_Ram_Int_Flt_Sts -> SWC_PLT_Appl_FaultMgr.Rp_PltToFltMgr_Mirror_Ram_Int_Flt_Sts  # UB:Derived from original system description
    connect SWC_PLT_Appl_Diag.Pp_PltToFltMgr_MMIC_A_MMIC_Diag -> SWC_PLT_Appl_FaultMgr.Rp_PltToFltMgr_MMIC_A_MMIC_Diag  # UB:Derived from original system description
    connect SWC_PLT_Appl_Diag.Pp_PltToFltMgr_MMIC_B_Diag -> SWC_PLT_Appl_FaultMgr.Rp_PltToFltMgr_MMIC_B_Diag  # UB:Derived from original system description
    connect SWC_PLT_Appl_Diag.Pp_Radar_Blockage_Flt_Sts -> SWC_PLT_Appl_FaultMgr.Rp_Radar_Blockage_Flt_Sts  # UB:Derived from original system description
    connect SWC_PLT_Appl_Diag.Pp_Radar_Interference_Flt_Sts -> SWC_PLT_Appl_FaultMgr.Rp_Radar_Interference_Flt_Sts  # UB:Derived from original system description
    connect SWC_PLT_Appl_Diag.Pp_Rdr_Hw_Tst -> SWC_PLT_Appl_FaultMgr.Rp_Rdr_Hw_Tst  # UB:Derived from original system description
    connect SWC_PLT_Appl_FaultMgr.Pp_RadarDiagRequestInterface -> SWC_PLT_Appl_ModeManager.Rp_RadarDiagRequest  # UB:Derived from original system description
    connect SWC_PLT_Appl_FaultMgr.Pp_ModeManagerTestResultInterface -> SWC_PLT_Appl_ModeManager.Rp_TR_ModeManager  # UB:Derived from original system description
    connect SWC_PLT_Appl_IoHwAb.CS_ThermMonTemp -> SWC_PLT_Appl_Diag.CS_ThermMonTemp  # UB:Derived from original system description
    connect SWC_PLT_Appl_ModeManager.Pp_OperationMode_System -> SWC_PLT_Appl_Diag.Rp_Operation_Mode_System  # UB:Derived from original system description
    connect SWC_PLT_CDD_MCU_Safety.Pp_PlatformInitializationStatus -> SWC_PLT_Appl_Diag.Rp_PlatformInitializationStatus  # UB:Derived from original system description
    connect SWC_PLT_CDD_MCU_Safety.Pp_TR_initMCU_Fail -> SWC_PLT_Appl_Diag.Rp_TR_initMCU_Fail  # UB:Derived from original system description
    connect SWC_PLT_CDD_MCU_Safety.Pp_PlatformInitializationStatus -> SWC_PLT_Appl_ModeManager.Rp_InitializationStatus  # UB:Derived from original system description
    connect SWC_PLT_Appl_PlatformTime.Get_PlatfromTime_us -> SWC_PLT_CDD_ECUSync.CS_Get_PlatfromTime_us  # UB:Derived from original system description
    connect SWC_PLT_Appl_PlatformTime.CS_PlatformTime_Fault_Injection -> SWC_PLT_CDD_XCP.CS_PlatformTime_Fault_Injection  # UB:Derived from original system description
    connect SWC_PLT_Appl_PlatformTime.CS_Get_Platform_Elapsed_ustime -> SWC_PLT_CDD_ECUSync.CS_Get_Platform_Elapsed_ustime  # UB:Derived from original system description
    connect SWC_PLT_CDD_Radar_Control.Pp_Radar_Init_Status -> SWC_PLT_CDD_XCP.Rp_Radar_Init_Status  # UB:Derived from original system description
    connect SWC_PLT_CDD_Radar_Control.Pp_Radar_CMD_Radiate -> SWC_PLT_CDD_XCP.Rp_Radar_CMD_Radiate  # UB:Derived from original system description
    connect SWC_PLT_Appl_ModeManager.Pp_CommandRadiate_Final -> SWC_PLT_CDD_Radar_Control.Rp_Command_Radiate_Final  # UB:Derived from original system description
    connect SWC_PLT_Appl_ModeManager.Pp_IsRadiateForced -> SWC_PLT_CDD_Radar_Control.Rp_IsRadiateForced  # UB:Derived from original system description
    connect SWC_PLT_CDD_Radar_Control.Pp_RadarCoreStatus -> SWC_PLT_Appl_ModeManager.Rp_RadarCoreStatus  # UB:Derived from original system description
    connect SWC_PLT_CDD_Radar_Control.Pp_Diag_MMIC_ErrorFlags -> SWC_PLT_Appl_Diag.Rp_Diag_MMIC_ErrorFlags  # UB:Derived from original system description
    connect SWC_PLT_CDD_XCP.Pp_XCP_Fault_Override -> SWC_PLT_Appl_FaultMgr.Rp_XCP_Fault_Override  # UB:Derived from original system description
    connect SWC_PLT_Appl_Diag.Pp_Alignment_Flt_Sts -> SWC_PLT_Appl_FaultMgr.Rp_Alignment_Flt_Sts  # UB:Derived from original system description
    connect SWC_PLT_Appl_Diag.Pp_IPC_Faults_sts -> SWC_PLT_Appl_FaultMgr.Rp_IPC_Faults_sts  # UB:Derived from original system description
    connect SWC_PLT_Appl_Diag.Pp_PltToFltMgr_InterProcessor_Commn -> SWC_PLT_Appl_FaultMgr.Rp_PltToFltMgr_InterProcessor_Commn  # UB:Derived from original system description
    connect SWC_PLT_Appl_Diag.Pp_PltToFltMgr_Memory_Diagnostics -> SWC_PLT_Appl_FaultMgr.Rp_PltToFltMgr_Memory_Diagnostics  # UB:Derived from original system description
    connect SWC_PLT_Appl_Diag.Pp_RFE_Repetitive_Fault_Status -> SWC_PLT_Appl_FaultMgr.Rp_RFE_Repetitive_Fault_Status  # UB:Derived from original system description
    connect SWC_PLT_Appl_Diag.Pp_TR_PlatformTime -> SWC_PLT_Appl_FaultMgr.Rp_TR_PlatformTime  # UB:Derived from original system description
    connect SWC_PLT_Appl_PlatformTime.Pp_TR_platform_Time -> SWC_PLT_Appl_Diag.Rp_TR_platform_Time  # UB:Derived from original system description
    connect SWC_PLT_Appl_PlatformTime.Get_PlatfromTime_us -> SWC_PLT_Appl_Diag.Pp_Get_PlatfromTime_us_diag  # UB:Derived from original system description
    connect SWC_PLT_CDD_FailSafe.Pp_Repetitive_Reset_Status -> SWC_PLT_Appl_Diag.Rp_Repetitive_Reset_Status  # UB:Derived from original system description
    connect SWC_PLT_CDD_FailSafe.Pp_RFE_Repetitive_Reset_Status -> SWC_PLT_Appl_Diag.Rp_RFE_Repetitive_Reset_Status  # UB:Derived from original system description
    connect SWC_PLT_CDD_FailSafe.FailSafe_Log_ResetReason -> SWC_PLT_Appl_Diag.FailSafe_Log_ResetReason  # UB:Derived from original system description
    connect SWC_PLT_Appl_IoHwAb.Pp_Vbatt_State -> SWC_PLT_Appl_Diag.Rp_VbattState  # UB:Derived from original system description
    connect SWC_CDD_IPC.Pp_IPC_Faults -> SWC_PLT_Appl_Diag.Rp_IPC_Faults  # UB:Derived from original system description
    connect SWC_CDD_IPC.Pp_RadarCapability_Faults -> SWC_PLT_Appl_Diag.Rp_RadarCapability_Faults  # UB:Derived from original system description
    delegate SWC_PLT_Radar_Alignment_Handler.Pp_Alignment_Faults <-> outer port Pp_Alignment_Faults  # UB:Derived from original system description
    connect SWC_PLT_Radar_Alignment_Handler.Pp_Alignment_Faults -> SWC_PLT_Appl_Diag.Rp_Alignment_Faults  # UB:Derived from original system description
    connect SWC_PLT_CDD_MCU_Safety.Pp_ECU_Reset -> SWC_PLT_Appl_ModeManager.Rp_ECU_Reset  # UB:Derived from original system description
    connect SWC_PLT_CDD_MCU_Safety.Pp_Fault_name_For_FHTI_Testing -> SWC_PLT_Appl_ModeManager.Rp_Fault_name_For_FHTI_Testing  # UB:Derived from original system description
    connect SWC_PLT_CDD_FailSafe.Pp_Fault_name_For_FHTI_Testing -> SWC_PLT_Appl_ModeManager.Rp_Fault_name_For_FHTI_Testing  # UB:Derived from original system description
    connect SWC_PLT_CDD_FailSafe.Pp_Repetitive_Reset_Status -> SWC_PLT_Appl_ModeManager.Rp_Repetitive_Reset_Status  # UB:Derived from original system description
    connect SWC_PLT_Appl_IoHwAb.Pp_Vbatt_State -> SWC_PLT_Appl_ModeManager.Rp_Vbattstate  # UB:Derived from original system description
    connect SWC_CDD_IPC.Pp_Fault_name_For_FHTI_Testing -> SWC_PLT_Appl_ModeManager.Rp_Fault_name_For_FHTI_Testing  # UB:Derived from original system description
    connect SWC_PLT_CDD_XCP.Pp_XCP_ADC_MCU_Temp_Override -> SWC_PLT_Appl_IoHwAb.Rp_XCP_ADC_MCU_Temp_Override  # UB:Derived from original system description
    connect SWC_PLT_Appl_IoHwAb.Pp_MCU_Sensor_Count -> SWC_PLT_CDD_XCP.Rp_MCU_Sensor_Count  # UB:Derived from original system description
    connect SWC_PLT_Appl_IoHwAb.Pp_Analog_Channel_Count -> SWC_PLT_CDD_XCP.Rp_Analog_Channel_Count  # UB:Derived from original system description
    connect SWC_PLT_Appl_IoHwAb.Pp_BoardRevision_Xcp -> SWC_PLT_CDD_XCP.Rp_BoardRevision_Xcp  # UB:Derived from original system description
    connect SWC_PLT_Appl_IoHwAb.CS_Platform_register_set -> SWC_PLT_Appl_PlatformTime.CS_Platform_register_set  # UB:Derived from original system description
    connect SWC_PLT_CDD_MCU_Safety.Pp_ID_data -> SWC_PLT_CDD_XCP.Rp_ID_data  # UB:Derived from original system description
    connect SWC_PLT_CDD_MCU_Safety.CS_MCU_Safety_Fault_Injection -> SWC_PLT_CDD_XCP.CS_MCU_Safety_Fault_Injection  # UB:Derived from original system description
    connect SWC_PLT_Appl_PlatformTime.Pp_TR_platform_Time -> SWC_PLT_CDD_MCU_Safety.Rp_TR_PlatformTime  # UB:Derived from original system description
    connect SWC_PLT_CDD_FailSafe.Pp_Repetitive_Reset_Status -> SWC_PLT_CDD_MCU_Safety.Rp_Repetitive_Reset_Status  # UB:Derived from original system description
    connect SWC_PLT_CDD_FailSafe.FailSafe_Log_ResetReason -> SWC_PLT_CDD_MCU_Safety.CS_MCU_Safety_FailSafe_ResetReason  # UB:Derived from original system description
    connect SWC_PLT_CDD_MCU_Safety.Pp_MemExceptionInfo -> SWC_PLT_CDD_FailSafe.Rp_MemExceptionInfo  # UB:Derived from original system description
    connect SWC_PLT_CDD_XCP.Pp_XCP_ForceRadiate -> SWC_PLT_Appl_ModeManager.Rp_XCP_ForceRadiate
    connect SWC_PLT_CDD_FailSafe.CS_FailSafe_Fault_Injection -> SWC_PLT_CDD_XCP.CS_FailSafe_Fault_Injection  # UB:Derived from original system description
    connect SWC_CDD_IPC.CS_IPC_Fault_Injection -> SWC_PLT_CDD_XCP.CS_IPC_Fault_Injection  # UB:Derived from original system description
    connect SWC_PLT_CDD_XCP.Pp_ADC_XCP_Req -> SWC_PLT_Service_IoHwAb.Rp_ADC_XCP_Req
    connect SWC_PLT_Service_IoHwAb.CS_RawAdcCount -> SWC_PLT_Appl_IoHwAb.CS_RawAdcCount
    connect SWC_PLT_Service_IoHwAb.CS_Update_Thermal_Mon_Temps -> SWC_PLT_Appl_IoHwAb.CS_Update_Thermal_Mon_Temps
    delegate SWC_PLT_Appl_Communication.Pp_SG_TrackerObject{001..003} <-> outer port Pp_SG_TrackerObject{001..003}  # UB:Derived from original system description
    delegate SWC_PLT_Appl_Communication.Pp_SG_TrackerObject{005..064} <-> outer port Pp_SG_TrackerObject{005..064}  # UB:Derived from original system description
    connect NvM.PS_SWC_PLT_Appl_NvMHandlerAlignment_NvMBlock -> SWC_PLT_Appl_NvMHandler.Rp_PS_Swc_Xcp_Alignment
    connect NvM.PS_SWC_PLT_Appl_NvMHandlerRFE_R1R2_Fault_NvM -> SWC_PLT_Appl_NvMHandler.Rp_SWC_PLT_CDD_Rfe_R1R2_Fault
    connect NvM.PS_SWC_PLT_Appl_NvMHandlerSWC_PLT_CDD_FailSafe -> SWC_PLT_Appl_NvMHandler.Rp_SWC_PLT_CDD_FailSafe_ResetReason
    connect NvM.PS_SWC_PLT_Appl_NvMHandlerBringup_NvMBlock -> SWC_PLT_Appl_NvMHandler.Rp_PS_Swc_NvMBringup
    connect SWC_PLT_Appl_IoHwAb.Pp_RawAdc_Data_UnFiltered -> SWC_PLT_CDD_XCP.Rp_RawAdc_Data_UnFiltered  # UB:Derived from original system description
    connect SWC_PLT_Appl_IoHwAb.Pp_RawAdc_Data_Filtered -> SWC_PLT_CDD_XCP.Rp_RawAdc_Data_Filtered  # UB:Derived from original system description
    connect SWC_PLT_Appl_IoHwAb.Pp_PhysicalAdcData -> SWC_PLT_CDD_XCP.Rp_PhysicalAdcData  # UB:Derived from original system description
    connect SWC_PLT_Appl_Communication.Pp_PCAN_Srv_DisableAppTx -> SWC_PLT_CDD_XCP.Rp_PCAN_Srv_DisableAppTx  # UB:Derived from original system description
    connect SWC_PLT_Appl_Communication.Pp_PCAN_Srv_EnableAppTx -> SWC_PLT_CDD_XCP.Rp_PCAN_Srv_EnableAppTx  # UB:Derived from original system description
    connect SWC_PLT_Radar_Alignment_Handler.Pp_Alignment_M2D_Data -> SWC_CDD_IPC.Rp_Alignment_M2D_Data
    connect SWC_PLT_Radar_Alignment_Handler.Pp_Auto_Alignment_Data -> SWC_PLT_CDD_XCP.Rp_Auto_Alignment_Data
    connect SWC_CDD_IPC.Pp_Alignment_IPC_Data -> SWC_PLT_Radar_Alignment_Handler.Rp_Alignment_IPC_Data
    connect SWC_PLT_CDD_XCP.Pp_Alignment_Type -> SWC_PLT_Radar_Alignment_Handler.Rp_Alignment_Type
    connect SWC_PLT_Radar_Alignment_Handler.Pp_initial_Alignment_Perform_Result -> SWC_PLT_CDD_XCP.Rp_initial_Alignment_Perform_Result
    connect SWC_PLT_Radar_Alignment_Handler.Pp_Initial_Alignment_Result -> SWC_PLT_CDD_XCP.Rp_Initial_Alignment_Result
    connect SWC_PLT_CDD_XCP.Pp_XCP_Alignment_Flag -> SWC_PLT_Radar_Alignment_Handler.Rp_XCP_Alignment_Flag
    connect SWC_PLT_Radar_Alignment_Handler.Pp_AlignmentAuto -> SWC_PLT_CDD_Logging.Rp_AlignmentAuto
    connect SWC_PLT_Radar_Alignment_Handler.Pp_Alignment_Handler -> SWC_PLT_CDD_Logging.Rp_Alignment_Handler
    connect SWC_PLT_Radar_Alignment_Handler.Pp_AlignmentService -> SWC_PLT_CDD_Logging.Rp_AlignmentService
    connect SWC_PLT_Radar_Alignment_Handler.Pp_AlignmentShortTrack -> SWC_PLT_CDD_Logging.Rp_AlignmentShortTrack
    connect SWC_PLT_Radar_Alignment_Handler.Pp_AlignmentStatic -> SWC_PLT_CDD_Logging.Rp_AlignmentStatic
    connect SWC_PLT_Appl_ModeManager.Pp_OperationMode_System -> SWC_PLT_Radar_Alignment_Handler.Rp_OperationMode_Type
    connect SWC_PLT_CDD_XCP.Pp_Alignment_Write_NvM_Data -> SWC_PLT_Radar_Alignment_Handler.Rp_Alignment_Write_NvM_Data
    connect SWC_PLT_Appl_NvMHandler.CS_Trigger_Write_to_NVM -> SWC_PLT_Radar_Alignment_Handler.CS_Trigger_Write_to_NVM
    connect SWC_PLT_CDD_ExternalWdg.CS_External_Watchdog_Fault_Injection -> SWC_PLT_CDD_XCP.CS_External_Watchdog_Fault_Injection  # UB:Derived from original system description
    connect SWC_PLT_CDD_ExternalWdg.Pp_external_watchdog_init_status -> SWC_PLT_CDD_MCU_Safety.Rp_external_watchdog_init_status  # UB:Derived from original system description
    connect SWC_PLT_CDD_ExternalWdg.Pp_externalwatchdogstatus -> SWC_PLT_Appl_Diag.Rp_externalwatchdogstatus  # UB:Derived from original system description
    connect SWC_PLT_Appl_Communication.Request_SDC_C_consService_RDR_1_ADAS_Vehicle_Status_2b1e055b -> BswM.Request_SDC_C_consService_RDR_1_ADAS_Vehicle_Status_2b1e055b
    connect BswM.Switch_SDC_Mode_S_provService_RDR_1_SW_Info_c2745ec9_EH_EventGroup_RDR_1_653e2581 -> SWC_PLT_Appl_Communication.Switch_SDC_Mode_S_provService_RDR_1_SW_Info_c2745ec9_EH_EventGroup_RDR_1_653e2581
    connect SWC_PLT_Appl_Communication.Request_SDC_S_provService_RDR_1_SW_Info_c2745ec9 -> BswM.Request_SDC_S_provService_RDR_1_SW_Info_c2745ec9
    connect SWC_PLT_Appl_Communication.Request_SDC_C_consService_RDR_1_ADAS_Vehicle_Status_2b1e055b_CEG_consServiceGrp_RDR_1_ADAS_Vehicle_Status_4b79da85 -> BswM.Request_SDC_C_consService_RDR_1_ADAS_Vehicle_Status_2b1e055b_CEG_consServiceGrp_RDR_1_ADAS_Vehicle_Status_4b79da85
    connect SWC_PLT_Appl_Communication.Request_SDC_S_provService_RDR_1_Detections_89f78c9f -> BswM.Request_SDC_S_provService_RDR_1_Detections_89f78c9f
    connect BswM.Switch_SDC_Mode_S_provService_RDR_1_Status_d2069d01_EH_EventGroup_RDR_1_f7c73cae -> SWC_PLT_Appl_Communication.Switch_SDC_Mode_S_provService_RDR_1_Status_d2069d01_EH_EventGroup_RDR_1_f7c73cae
    connect BswM.Switch_SDC_Mode_S_provService_RDR_1_Detections_89f78c9f_EH_EventGroup_RDR_1_ca62382d -> SWC_PLT_Appl_Communication.Switch_SDC_Mode_S_provService_RDR_1_Detections_89f78c9f_EH_EventGroup_RDR_1_ca62382d
    connect SWC_PLT_Appl_Communication.Request_SDC_S_provService_RDR_1_Status_d2069d01 -> BswM.Request_SDC_S_provService_RDR_1_Status_d2069d01
    connect BswM.Switch_SDC_Mode_C_consService_RDR_1_ADAS_Vehicle_Status_2b1e055b -> SWC_PLT_Appl_Communication.Switch_SDC_Mode_C_consService_RDR_1_ADAS_Vehicle_Status_2b1e055b
    connect BswM.Switch_SDC_Mode_C_consService_RDR_1_ADAS_Vehicle_Status_2b1e055b_CEG_consServiceGrp_RDR_1_ADAS_Vehicle_Status_4b79da85 -> SWC_PLT_Appl_Communication.Switch_SDC_Mode_C_consService_RDR_1_ADAS_Vehicle_Status_2b1e055b_CEG_consServiceGrp_RDR_1_ADAS_Vehicle_Status_4b79da85
    connect SWC_PLT_CDD_Radar_Control.CS_Radar_control_Fault_Injection -> SWC_PLT_CDD_XCP.CS_Radar_control_Fault_Injection  # UB:Derived from original system description
    connect SWC_PLT_CDD_WdgHandler.CS_Wdg_Disable -> SWC_PLT_Appl_IntWDG.CS_Wdg_Disable  # UB:Derived from original system description
    connect SWC_PLT_Appl_ModeManager.CS_Modemanager_Fault_Injection -> SWC_PLT_CDD_XCP.CS_Modemanager_Fault_Injection  # UB:Derived from original system description
    connect SWC_PLT_Appl_Diag.CS_Diag_Fault_Injection -> SWC_PLT_CDD_XCP.CS_Diag_Fault_Injection  # UB:Derived from original system description
    connect SWC_Appl_Project.CS_Signal_Integrity_Fault_Injection -> SWC_PLT_CDD_XCP.CS_Signal_Integrity_Fault_Injection  # UB:Derived from original system description
    connect SWC_PLT_CDD_Radar_Control.Pp_MMIC_Temperature -> SWC_PLT_CDD_XCP.Rp_MMIC_Temperature  # UB:Derived from original system description
    connect SWC_PLT_CDD_XCP.Pp_XCP_Set_Output_State -> SWC_Appl_Project.Rp_XCP_Set_Output_State
    connect SWC_PLT_CDD_Radar_Control.Pp_MMIC_Count -> SWC_PLT_CDD_XCP.Rp_MMIC_Count  # UB:Derived from original system description
    connect SWC_PLT_Appl_IoHwAb.CS_ThermMonTemp -> SWC_PLT_CDD_XCP.CS_ThermMonTemp
    connect SWC_PLT_CDD_FailSafe.Pp_FailSafe_ResetReason -> SWC_PLT_CDD_Logging.Rp_FailSafe_ResetReason  # UB:Derived from original system description
    connect SWC_PLT_CDD_FailSafe.Pp_FailSafe_ResetReason -> SWC_PLT_Appl_NvMHandler.Rp_FailSafe_ResetReason
    connect SWC_PLT_Appl_NvMHandler.CS_Trigger_Write_to_NVM -> SWC_PLT_CDD_FailSafe.CS_Trigger_Write_to_NVM  # UB:Derived from original system description
    connect SWC_PLT_Appl_NvMHandler.Pp_FailSafe_ResetReason -> SWC_PLT_CDD_FailSafe.Rp_FailSafe_ResetReason
    delegate SWC_PLT_Appl_Communication.Pp_RDR_NM_CAN_NM_State <-> outer port Pp_RDR_NM_CAN_NM_State  # UB:Derived from original system description
    delegate SWC_PLT_Appl_Communication.Pp_RDR_NM_CBV_ActWakeBit_4 <-> outer port Pp_RDR_NM_CBV_ActWakeBit_4  # UB:Derived from original system description
    delegate SWC_PLT_Appl_Communication.Pp_RDR_NM_CBV_NMCoordBit_3 <-> outer port Pp_RDR_NM_CBV_NMCoordBit_3  # UB:Derived from original system description
    delegate SWC_PLT_Appl_Communication.Pp_RDR_NM_CBV_PNIBit_6 <-> outer port Pp_RDR_NM_CBV_PNIBit_6  # UB:Derived from original system description
    delegate SWC_PLT_Appl_Communication.Pp_RDR_NM_CBV_ReptMsgBit0 <-> outer port Pp_RDR_NM_CBV_ReptMsgBit0  # UB:Derived from original system description
    delegate SWC_PLT_Appl_Communication.Pp_RDR_NM_CBV_ResdBit_1 <-> outer port Pp_RDR_NM_CBV_ResdBit_1  # UB:Derived from original system description
    delegate SWC_PLT_Appl_Communication.Pp_RDR_NM_CBV_ResdBit_2 <-> outer port Pp_RDR_NM_CBV_ResdBit_2  # UB:Derived from original system description
    delegate SWC_PLT_Appl_Communication.Pp_RDR_NM_CBV_ResdBit_5 <-> outer port Pp_RDR_NM_CBV_ResdBit_5  # UB:Derived from original system description
    delegate SWC_PLT_Appl_Communication.Pp_RDR_NM_CBV_ResdBit_7 <-> outer port Pp_RDR_NM_CBV_ResdBit_7  # UB:Derived from original system description
    delegate SWC_PLT_Appl_Communication.Pp_RDR_NM_PN_User_Data <-> outer port Pp_RDR_NM_PN_User_Data  # UB:Derived from original system description
    delegate SWC_PLT_Appl_Communication.Pp_RDR_NM_PNC_Reserved{1..3} <-> outer port Pp_RDR_NM_PNC_Reserved{1..3}  # UB:Derived from original system description
    delegate SWC_PLT_Appl_Communication.Pp_RDR_NM_Wakeup_And_Reason <-> outer port Pp_RDR_NM_Wakeup_And_Reason  # UB:Derived from original system description
    delegate SWC_PLT_Appl_Communication.Pp_SG_TrackerHeader <-> outer port Pp_SG_TrackerHeader  # UB:Derived from original system description
    delegate SWC_PLT_Appl_Communication.Pp_SG_TrackerStatus <-> outer port Pp_SG_TrackerStatus  # UB:Derived from original system description
    delegate SWC_PLT_Appl_Communication.Rp_TSYN_OVS <-> outer port Rp_TSYN_OVS  # UB:Derived from original system description
    delegate SWC_PLT_Appl_Communication.Rp_TSYN_PDU <-> outer port Rp_TSYN_PDU  # UB:Derived from original system description
    delegate SWC_PLT_Appl_Communication.Rp_TSYN_RESERVED <-> outer port Rp_TSYN_RESERVED  # UB:Derived from original system description
    delegate SWC_PLT_Appl_Communication.Rp_TSYN_SEQUENCE_COUNTER <-> outer port Rp_TSYN_SEQUENCE_COUNTER  # UB:Derived from original system description
    delegate SWC_PLT_Appl_Communication.Rp_TSYN_SGW <-> outer port Rp_TSYN_SGW  # UB:Derived from original system description
    delegate SWC_PLT_Appl_Communication.Rp_TSYN_SYNCTIME_NANOSEC <-> outer port Rp_TSYN_SYNCTIME_NANOSEC  # UB:Derived from original system description
    delegate SWC_PLT_Appl_Communication.Rp_TSYN_SYNCTIME_SEC <-> outer port Rp_TSYN_SYNCTIME_SEC  # UB:Derived from original system description
    delegate SWC_PLT_Appl_Communication.Rp_TSYN_TIMEDOMAIN <-> outer port Rp_TSYN_TIMEDOMAIN  # UB:Derived from original system description
    delegate SWC_PLT_Appl_Communication.Rp_TSYN_USERBYTE <-> outer port Rp_TSYN_USERBYTE  # UB:Derived from original system description
    delegate SWC_PLT_Appl_Communication.Rp_TSYNC_CRC <-> outer port Rp_TSYNC_CRC  # UB:Derived from original system description
    connect SWC_PLT_CDD_WdgHandler.CS_WdgHandler_Fault_Injection -> SWC_PLT_CDD_XCP.CS_WdgHandler_Fault_Injection  # UB:Derived from original system description
    connect SWC_PLT_CDD_XCP.Pp_Hil_Activation -> SWC_PLT_CDD_HIL.Rp_Hil_Activation  # UB:Derived from original system description
    connect SWC_PLT_CDD_FCRU.Pp_PMU_FaultB_PinIntegrity -> SWC_PLT_CDD_MCU_Safety.Rp_PMU_FaultB_PinIntegrity  # UB:Derived from original system description
    connect SWC_PLT_CDD_MCU_Safety.Pp_MPU_lock_sts -> SWC_PLT_CDD_XCP.Rp_MPU_lock_sts  # UB:Derived from original system description
    connect SWC_PLT_CDD_XCP.Pp_MPU_lock_request -> SWC_PLT_CDD_MCU_Safety.Rp_MPU_lock_request  # UB:Derived from original system description
    connect SWC_CDD_IPC.Pp_HIL_Periodic_Handler -> SWC_PLT_CDD_HIL.Rp_HIL_Periodic_Handler  # UB:Derived from original system description
    connect SWC_CDD_IPC.Pp_StaticRegCheckFailureInfo -> SWC_PLT_CDD_MCU_Safety.Rp_StaticRegCheckFailureInfo  # UB:Derived from original system description
    connect SWC_PLT_CDD_MCU_Safety.Pp_StaticRegCheckFailureInfo -> SWC_PLT_CDD_FailSafe.Rp_StaticRegCheckFailureInfo  # UB:Derived from original system description
    connect SWC_PLT_Appl_NvMHandler.CS_Pp_Trigger_Write_to_NvM -> SWC_PLT_Radar_Alignment_Handler.CS_Rp_Trigger_Write_to_NvM  # UB:Derived from original system description
    connect SWC_PLT_Radar_Alignment_Handler.Pp_Align_Write_Nvm_Record -> SWC_PLT_Appl_NvMHandler.Rp_Align_Write_Nvm_Record  # UB:Derived from original system description
    connect SWC_PLT_Appl_IntWDG.CS_Disable_Wdg_Supervised_Entites -> SWC_PLT_CDD_Radar_Control.CS_Disable_Wdg_Supervised_Entites  # UB:Derived from original system description
    connect SWC_PLT_CDD_WdgHandler.Pp_Internal_Wdg_Fail_Status -> SWC_PLT_CDD_ExternalWdg.Rp_Internal_Wdg_Fail_Status  # UB:Derived from original system description
    connect StbM.GlobalTime_Slave_StbMSynchronizedTimeBase_CanTsync -> SWC_PLT_CDD_ECUSync.Pp_GlobalTime_Slave_StbMSynchronizedTimeBase_CanTsync
    connect SWC_PLT_CDD_FCRU.CS_FCRU_Fault_Injection -> SWC_PLT_CDD_XCP.CS_FCRU_Fault_Injection  # UB:Derived from original system description
    connect SWC_PLT_CDD_MCU_Safety.Pp_ECU_Reset -> SWC_PLT_CDD_XCP.Rp_ECU_Reset
    connect SWC_PLT_Appl_NvMHandler.Pp_Alignment_NvM_Read_Record -> SWC_PLT_CDD_XCP.Rp_Alignment_NvM_Read_Record  # UB:Derived from original system description
    connect SWC_PLT_Appl_FaultMgr.Pp_Active_Fault_Table -> SWC_PRJ_Appl_FaultMgr.Rp_ActiveFaultTable  # UB:Derived from original system description
    connect SWC_PLT_Appl_FaultMgr.Pp_Fault_Test_Complete_Table -> SWC_PRJ_Appl_FaultMgr.Rp_FaultTestCompleteTable  # UB:Derived from original system description
    connect SWC_PLT_Appl_FaultMgr.Pp_HistoryFaultTable -> SWC_PRJ_Appl_FaultMgr.Rp_HistoryFaultTable  # UB:Derived from original system description
    connect SWC_PRJ_Appl_FaultMgr.Pp_ActiveFaultTable -> SWC_PLT_CDD_XCP.Rp_Active_Fault_Table
    connect SWC_PRJ_Appl_FaultMgr.Pp_ActiveFaultLatchTable -> SWC_PLT_CDD_XCP.Rp_Active_Fault_Latch_Table
    connect SWC_PRJ_Appl_FaultMgr.Pp_HistoryFaultTable -> SWC_PLT_CDD_XCP.Rp_HistoryFaultTable
    connect SWC_PRJ_Appl_FaultMgr.Pp_FaultTestCompleteTable -> SWC_PLT_CDD_XCP.Rp_Fault_Test_Complete_Table
    connect SWC_PLT_Appl_NvMHandler.Pp_NvM_flag_status -> SWC_PLT_CDD_XCP.Rp_NvM_flag_status  # UB:Derived from original system description
    connect SWC_PLT_CDD_FailSafe.FailSafe_Log_ResetReason -> SWC_PLT_CDD_Radar_Control.CS_FailSafe_Log_ResetReason
    connect SWC_PLT_CDD_WdgHandler.Pp_Wdg_Fault_Injection_Request_IntWdg -> SWC_PLT_Appl_IntWDG.Rp_Wdg_Fault_Injection_Request_IntWdg
    connect SWC_PLT_CDD_WdgHandler.Pp_Wdg_Fault_Injection_Request_ExtWdg -> SWC_PLT_CDD_ExternalWdg.Rp_Wdg_Fault_Injection_Request_ExtWdg
    connect SWC_PLT_CDD_XCP.Pp_XCP_Phase_Rotator_Calibration -> SWC_PLT_CDD_Radar_Control.Rp_XCP_Phase_Rotator_Calibration  # UB:Derived from original system description
    connect StbM.GlobalTime_Slave_StbMSynchronizedTimeBase -> SWC_PLT_CDD_TimeSync.Pp_GlobalTime_Slave_StbMSynchronizedTimeBase
    connect StbM.GlobalTime_StatusEvent_StbMSynchronizedTimeBase -> SWC_PLT_CDD_TimeSync.Rp_StbMStatusNotificationCallback_StbMSynchronizedTimeBase
    connect SWC_PLT_Appl_RTM.Pp_CPU_Load -> SWC_PLT_CDD_Logging.Rp_CPU_Load  # UB:Derived from original system description
    connect SWC_PLT_CDD_FailSafe.CS_Failsafe_Log_ResetReason_at_Startup -> SWC_PLT_CDD_FCRU.CS_Failsafe_Log_ResetReason_at_Startup
    connect SWC_PLT_Appl_NvMHandler.Pp_Alignment_NvM_Data -> SWC_PLT_Radar_Alignment_Handler.Rp_Alignment_NvM_Data
    connect SWC_PLT_CDD_XCP.Pp_XCP_Ethernet_En_Dis -> SWC_PLT_CDD_Logging.Rp_XCP_Ethernet_En_Dis  # UB:Derived from original system description
    connect SWC_PLT_Appl_RTM.CS_Rtm_task_measurement -> SWC_PLT_CDD_Logging.CS_Rtm_task_measurement  # UB:Derived from original system description
    connect SWC_PRJ_Appl_FaultMgr.Pp_HistoryFaultTable -> SWC_PLT_CDD_Logging.Rp_HistoryFaultTable
    connect SWC_PLT_Appl_NvMHandler.CS_Trigger_Write_to_NVM -> SWC_PLT_CDD_Radar_Control.CS_Radar_Control_Rfe_R1R2_NvM_Write  # UB:Derived from original system description
    connect SWC_PLT_CDD_FailSafe.Pp_Hardware_Fault_Status -> SWC_PLT_Appl_Diag.Rp_Hardware_Fault_Status  # UB:Derived from original system description
    connect SWC_PLT_Appl_FaultMgr.Pp_Active_Fault_Latch_Table -> SWC_PRJ_Appl_FaultMgr.Rp_ActiveFaultLatchTable
    connect SWC_PLT_CDD_Logging.PostRadarProcessing_Detection -> SWC_CDD_IPC.PostRadarProcessing_Detection  # UB:Derived from original system description
    connect SWC_PLT_CDD_Logging.PostRadarProcessing_Radar_Capability -> SWC_CDD_IPC.PostRadarProcessing_Radar_Capability  # UB:Derived from original system description
    connect SWC_PLT_CDD_Logging.PostRadarProcessing_Header -> SWC_CDD_IPC.PostRadarProcessing_Header  # UB:Derived from original system description
    connect SWC_PLT_CDD_Logging.PostRadarProcessing_Debug -> SWC_CDD_IPC.PostRadarProcessing_Debug  # UB:Derived from original system description
    connect SWC_PLT_CDD_Logging.PostRadarProcessing_MMIC -> SWC_CDD_IPC.PostRadarProcessing_MMIC  # UB:Derived from original system description
    connect SWC_PLT_CDD_Logging.PostRadarProcessing_RDD -> SWC_CDD_IPC.PostRadarProcessing_RDD  # UB:Derived from original system description
    connect SWC_PLT_CDD_Logging.PostRadarProcessing_Status -> SWC_CDD_IPC.PostRadarProcessing_Status  # UB:Derived from original system description
    connect SWC_PLT_CDD_Radar_Control.Pp_Radar_Ctl_Look_Trigger -> SWC_CDD_IPC.Pp_Radar_Ctl_Look_Trigger  # UB:Derived from original system description
    delegate SWC_PLT_Appl_Communication.Pp_SG_AlignmentStatus1_AL <-> outer port Pp_SG_AlignmentStatus1_AL  # UB:Derived from original system description
    delegate SWC_PLT_Appl_Communication.Pp_SG_AlignmentStatus2_AL <-> outer port Pp_SG_AlignmentStatus2_AL  # UB:Derived from original system description
    delegate SWC_PLT_Appl_Communication.Pp_SG_Detections_001_004_AL <-> outer port Pp_SG_Detections_001_004_AL  # UB:Derived from original system description
    delegate SWC_PLT_Appl_Communication.Pp_SG_Detections_005_008_AL <-> outer port Pp_SG_Detections_005_008_AL  # UB:Derived from original system description
    delegate SWC_PLT_Appl_Communication.Pp_SG_Detections_009_012_AL <-> outer port Pp_SG_Detections_009_012_AL  # UB:Derived from original system description
    delegate SWC_PLT_Appl_Communication.Pp_SG_Detections_013_016_AL <-> outer port Pp_SG_Detections_013_016_AL  # UB:Derived from original system description
    delegate SWC_PLT_Appl_Communication.Pp_SG_Detections_017_020_AL <-> outer port Pp_SG_Detections_017_020_AL  # UB:Derived from original system description
    delegate SWC_PLT_Appl_Communication.Pp_SG_Detections_021_024_AL <-> outer port Pp_SG_Detections_021_024_AL  # UB:Derived from original system description
    delegate SWC_PLT_Appl_Communication.Pp_SG_Detections_025_028_AL <-> outer port Pp_SG_Detections_025_028_AL  # UB:Derived from original system description
    delegate SWC_PLT_Appl_Communication.Pp_SG_Detections_045_048_AL <-> outer port Pp_SG_Detections_045_048_AL  # UB:Derived from original system description
    delegate SWC_PLT_Appl_Communication.Pp_SG_Detections_029_032_AL <-> outer port Pp_SG_Detections_029_032_AL  # UB:Derived from original system description
    delegate SWC_PLT_Appl_Communication.Pp_SG_Detections_033_036_AL <-> outer port Pp_SG_Detections_033_036_AL  # UB:Derived from original system description
    delegate SWC_PLT_Appl_Communication.Pp_SG_Detections_037_040_AL <-> outer port Pp_SG_Detections_037_040_AL  # UB:Derived from original system description
    delegate SWC_PLT_Appl_Communication.Pp_SG_Detections_041_044_AL <-> outer port Pp_SG_Detections_041_044_AL  # UB:Derived from original system description
    delegate SWC_PLT_Appl_Communication.Pp_SG_Detections_097_100_AL <-> outer port Pp_SG_Detections_097_100_AL  # UB:Derived from original system description
    delegate SWC_PLT_Appl_Communication.Pp_SG_Detections_049_052_AL <-> outer port Pp_SG_Detections_049_052_AL  # UB:Derived from original system description
    delegate SWC_PLT_Appl_Communication.Pp_SG_Detections_053_056_AL <-> outer port Pp_SG_Detections_053_056_AL  # UB:Derived from original system description
    delegate SWC_PLT_Appl_Communication.Pp_SG_Detections_057_060_AL <-> outer port Pp_SG_Detections_057_060_AL  # UB:Derived from original system description
    delegate SWC_PLT_Appl_Communication.Pp_SG_Detections_061_064_AL <-> outer port Pp_SG_Detections_061_064_AL  # UB:Derived from original system description
    delegate SWC_PLT_Appl_Communication.Pp_SG_Detections_065_068_AL <-> outer port Pp_SG_Detections_065_068_AL  # UB:Derived from original system description
    delegate SWC_PLT_Appl_Communication.Pp_SG_Detections_069_072_AL <-> outer port Pp_SG_Detections_069_072_AL  # UB:Derived from original system description
    delegate SWC_PLT_Appl_Communication.Pp_SG_Detections_073_076_AL <-> outer port Pp_SG_Detections_073_076_AL  # UB:Derived from original system description
    delegate SWC_PLT_Appl_Communication.Pp_SG_Detections_077_080_AL <-> outer port Pp_SG_Detections_077_080_AL  # UB:Derived from original system description
    delegate SWC_PLT_Appl_Communication.Pp_SG_Detections_081_084_AL <-> outer port Pp_SG_Detections_081_084_AL  # UB:Derived from original system description
    delegate SWC_PLT_Appl_Communication.Pp_SG_Detections_085_088_AL <-> outer port Pp_SG_Detections_085_088_AL  # UB:Derived from original system description
    delegate SWC_PLT_Appl_Communication.Pp_SG_Detections_089_092_AL <-> outer port Pp_SG_Detections_089_092_AL  # UB:Derived from original system description
    delegate SWC_PLT_Appl_Communication.Pp_SG_Detections_093_096_AL <-> outer port Pp_SG_Detections_093_096_AL  # UB:Derived from original system description
    delegate SWC_PLT_Appl_Communication.Pp_SG_Detections_101_104_AL <-> outer port Pp_SG_Detections_101_104_AL  # UB:Derived from original system description
    delegate SWC_PLT_Appl_Communication.Pp_SG_Detections_105_108_AL <-> outer port Pp_SG_Detections_105_108_AL  # UB:Derived from original system description
    delegate SWC_PLT_Appl_Communication.Pp_SG_Detections_109_112_AL <-> outer port Pp_SG_Detections_109_112_AL  # UB:Derived from original system description
    delegate SWC_PLT_Appl_Communication.Pp_SG_Detections_113_116_AL <-> outer port Pp_SG_Detections_113_116_AL  # UB:Derived from original system description
    delegate SWC_PLT_Appl_Communication.Pp_SG_Detections_117_120_AL <-> outer port Pp_SG_Detections_117_120_AL  # UB:Derived from original system description
    delegate SWC_PLT_Appl_Communication.Pp_SG_Detections_121_124_AL <-> outer port Pp_SG_Detections_121_124_AL  # UB:Derived from original system description
    delegate SWC_PLT_Appl_Communication.Pp_SG_Detections_125_128_AL <-> outer port Pp_SG_Detections_125_128_AL  # UB:Derived from original system description
    delegate SWC_PLT_Appl_Communication.Pp_SG_Detections_129_132_AL <-> outer port Pp_SG_Detections_129_132_AL  # UB:Derived from original system description
    delegate SWC_PLT_Appl_Communication.Pp_SG_Detections_133_136_AL <-> outer port Pp_SG_Detections_133_136_AL  # UB:Derived from original system description
    delegate SWC_PLT_Appl_Communication.Pp_SG_Detections_137_140_AL <-> outer port Pp_SG_Detections_137_140_AL  # UB:Derived from original system description
    delegate SWC_PLT_Appl_Communication.Pp_SG_Detections_141_144_AL <-> outer port Pp_SG_Detections_141_144_AL  # UB:Derived from original system description
    delegate SWC_PLT_Appl_Communication.Pp_SG_Detections_145_148_AL <-> outer port Pp_SG_Detections_145_148_AL  # UB:Derived from original system description
    delegate SWC_PLT_Appl_Communication.Pp_SG_Detections_149_152_AL <-> outer port Pp_SG_Detections_149_152_AL  # UB:Derived from original system description
    delegate SWC_PLT_Appl_Communication.Pp_SG_Detections_153_156_AL <-> outer port Pp_SG_Detections_153_156_AL  # UB:Derived from original system description
    delegate SWC_PLT_Appl_Communication.Pp_SG_Detections_157_160_AL <-> outer port Pp_SG_Detections_157_160_AL  # UB:Derived from original system description
    delegate SWC_PLT_Appl_Communication.Pp_SG_Detections_161_164_AL <-> outer port Pp_SG_Detections_161_164_AL  # UB:Derived from original system description
    delegate SWC_PLT_Appl_Communication.Pp_SG_Detections_165_168_AL <-> outer port Pp_SG_Detections_165_168_AL  # UB:Derived from original system description
    delegate SWC_PLT_Appl_Communication.Pp_SG_Detections_169_172_AL <-> outer port Pp_SG_Detections_169_172_AL  # UB:Derived from original system description
    delegate SWC_PLT_Appl_Communication.Pp_SG_Detections_173_176_AL <-> outer port Pp_SG_Detections_173_176_AL  # UB:Derived from original system description
    delegate SWC_PLT_Appl_Communication.Pp_SG_Detections_177_180_AL <-> outer port Pp_SG_Detections_177_180_AL  # UB:Derived from original system description
    delegate SWC_PLT_Appl_Communication.Pp_SG_Detections_181_184_AL <-> outer port Pp_SG_Detections_181_184_AL  # UB:Derived from original system description
    delegate SWC_PLT_Appl_Communication.Pp_SG_Detections_185_188_AL <-> outer port Pp_SG_Detections_185_188_AL  # UB:Derived from original system description
    delegate SWC_PLT_Appl_Communication.Pp_SG_Detections_189_192_AL <-> outer port Pp_SG_Detections_189_192_AL  # UB:Derived from original system description
    delegate SWC_PLT_Appl_Communication.Pp_SG_Detections_193_196_AL <-> outer port Pp_SG_Detections_193_196_AL  # UB:Derived from original system description
    delegate SWC_PLT_Appl_Communication.Pp_SG_Detections_197_200_AL <-> outer port Pp_SG_Detections_197_200_AL  # UB:Derived from original system description
    delegate SWC_PLT_Appl_Communication.Pp_SG_Detections_201_204_AL <-> outer port Pp_SG_Detections_201_204_AL  # UB:Derived from original system description
    delegate SWC_PLT_Appl_Communication.Pp_SG_Detections_205_208_AL <-> outer port Pp_SG_Detections_205_208_AL  # UB:Derived from original system description
    delegate SWC_PLT_Appl_Communication.Pp_SG_Detections_209_212_AL <-> outer port Pp_SG_Detections_209_212_AL  # UB:Derived from original system description
    delegate SWC_PLT_Appl_Communication.Pp_SG_Detections_213_216_AL <-> outer port Pp_SG_Detections_213_216_AL  # UB:Derived from original system description
    delegate SWC_PLT_Appl_Communication.Pp_SG_Detections_217_220_AL <-> outer port Pp_SG_Detections_217_220_AL  # UB:Derived from original system description
    delegate SWC_PLT_Appl_Communication.Pp_SG_Detections_221_224_AL <-> outer port Pp_SG_Detections_221_224_AL  # UB:Derived from original system description
    delegate SWC_PLT_Appl_Communication.Pp_SG_Detections_225_228_AL <-> outer port Pp_SG_Detections_225_228_AL  # UB:Derived from original system description
    delegate SWC_PLT_Appl_Communication.Pp_SG_Detections_229_232_AL <-> outer port Pp_SG_Detections_229_232_AL  # UB:Derived from original system description
    delegate SWC_PLT_Appl_Communication.Pp_SG_Detections_233_236_AL <-> outer port Pp_SG_Detections_233_236_AL  # UB:Derived from original system description
    delegate SWC_PLT_Appl_Communication.Pp_SG_Detections_237_240_AL <-> outer port Pp_SG_Detections_237_240_AL  # UB:Derived from original system description
    delegate SWC_PLT_Appl_Communication.Pp_SG_Detections_241_244_AL <-> outer port Pp_SG_Detections_241_244_AL  # UB:Derived from original system description
    delegate SWC_PLT_Appl_Communication.Pp_SG_Detections_245_248_AL <-> outer port Pp_SG_Detections_245_248_AL  # UB:Derived from original system description
    delegate SWC_PLT_Appl_Communication.Pp_SG_Detections_249_252_AL <-> outer port Pp_SG_Detections_249_252_AL  # UB:Derived from original system description
    delegate SWC_PLT_Appl_Communication.Pp_SG_Detections_253_256_AL <-> outer port Pp_SG_Detections_253_256_AL  # UB:Derived from original system description
    delegate SWC_PLT_Appl_Communication.Pp_SG_Detections_257_260_AL <-> outer port Pp_SG_Detections_257_260_AL  # UB:Derived from original system description
    delegate SWC_PLT_Appl_Communication.Pp_SG_Detections_261_264_AL <-> outer port Pp_SG_Detections_261_264_AL  # UB:Derived from original system description
    delegate SWC_PLT_Appl_Communication.Pp_SG_Detections_265_268_AL <-> outer port Pp_SG_Detections_265_268_AL  # UB:Derived from original system description
    delegate SWC_PLT_Appl_Communication.Pp_SG_Detections_269_272_AL <-> outer port Pp_SG_Detections_269_272_AL  # UB:Derived from original system description
    delegate SWC_PLT_Appl_Communication.Pp_SG_Detections_273_276_AL <-> outer port Pp_SG_Detections_273_276_AL  # UB:Derived from original system description
    delegate SWC_PLT_Appl_Communication.Pp_SG_Detections_277_280_AL <-> outer port Pp_SG_Detections_277_280_AL  # UB:Derived from original system description
    delegate SWC_PLT_Appl_Communication.Pp_SG_Detections_281_284_AL <-> outer port Pp_SG_Detections_281_284_AL  # UB:Derived from original system description
    delegate SWC_PLT_Appl_Communication.Pp_SG_Detections_285_288_AL <-> outer port Pp_SG_Detections_285_288_AL  # UB:Derived from original system description
    delegate SWC_PLT_Appl_Communication.Pp_SG_Detections_289_292_AL <-> outer port Pp_SG_Detections_289_292_AL  # UB:Derived from original system description
    delegate SWC_PLT_Appl_Communication.Pp_SG_Detections_293_296_AL <-> outer port Pp_SG_Detections_293_296_AL  # UB:Derived from original system description
    delegate SWC_PLT_Appl_Communication.Pp_SG_Detections_297_300_AL <-> outer port Pp_SG_Detections_297_300_AL  # UB:Derived from original system description
    delegate SWC_PLT_Appl_Communication.Pp_SG_Detections_301_304_AL <-> outer port Pp_SG_Detections_301_304_AL  # UB:Derived from original system description
    delegate SWC_PLT_Appl_Communication.Pp_SG_Detections_305_308_AL <-> outer port Pp_SG_Detections_305_308_AL  # UB:Derived from original system description
    delegate SWC_PLT_Appl_Communication.Pp_SG_Detections_309_312_AL <-> outer port Pp_SG_Detections_309_312_AL  # UB:Derived from original system description
    delegate SWC_PLT_Appl_Communication.Pp_SG_Detections_313_316_AL <-> outer port Pp_SG_Detections_313_316_AL  # UB:Derived from original system description
    delegate SWC_PLT_Appl_Communication.Pp_SG_Detections_317_320_AL <-> outer port Pp_SG_Detections_317_320_AL  # UB:Derived from original system description
    delegate SWC_PLT_Appl_Communication.Pp_SG_Detections_321_324_AL <-> outer port Pp_SG_Detections_321_324_AL  # UB:Derived from original system description
    delegate SWC_PLT_Appl_Communication.Pp_SG_Detections_325_328_AL <-> outer port Pp_SG_Detections_325_328_AL  # UB:Derived from original system description
    delegate SWC_PLT_Appl_Communication.Pp_SG_Detections_329_332_AL <-> outer port Pp_SG_Detections_329_332_AL  # UB:Derived from original system description
    delegate SWC_PLT_Appl_Communication.Pp_SG_Detections_333_336_AL <-> outer port Pp_SG_Detections_333_336_AL  # UB:Derived from original system description
    delegate SWC_PLT_Appl_Communication.Pp_SG_Detections_337_340_AL <-> outer port Pp_SG_Detections_337_340_AL  # UB:Derived from original system description
    delegate SWC_PLT_Appl_Communication.Pp_SG_Detections_341_344_AL <-> outer port Pp_SG_Detections_341_344_AL  # UB:Derived from original system description
    delegate SWC_PLT_Appl_Communication.Pp_SG_Detections_345_348_AL <-> outer port Pp_SG_Detections_345_348_AL  # UB:Derived from original system description
    delegate SWC_PLT_Appl_Communication.Pp_SG_Detections_349_352_AL <-> outer port Pp_SG_Detections_349_352_AL  # UB:Derived from original system description
    delegate SWC_PLT_Appl_Communication.Pp_SG_Detections_353_356_AL <-> outer port Pp_SG_Detections_353_356_AL  # UB:Derived from original system description
    delegate SWC_PLT_Appl_Communication.Pp_SG_Detections_357_360_AL <-> outer port Pp_SG_Detections_357_360_AL  # UB:Derived from original system description
    delegate SWC_PLT_Appl_Communication.Pp_SG_Detections_361_364_AL <-> outer port Pp_SG_Detections_361_364_AL  # UB:Derived from original system description
    delegate SWC_PLT_Appl_Communication.Pp_SG_Detections_365_368_AL <-> outer port Pp_SG_Detections_365_368_AL  # UB:Derived from original system description
    delegate SWC_PLT_Appl_Communication.Pp_SG_Detections_369_372_AL <-> outer port Pp_SG_Detections_369_372_AL  # UB:Derived from original system description
    delegate SWC_PLT_Appl_Communication.Pp_SG_Detections_373_376_AL <-> outer port Pp_SG_Detections_373_376_AL  # UB:Derived from original system description
    delegate SWC_PLT_Appl_Communication.Pp_SG_Detections_377_380_AL <-> outer port Pp_SG_Detections_377_380_AL  # UB:Derived from original system description
    delegate SWC_PLT_Appl_Communication.Pp_SG_Detections_381_384_AL <-> outer port Pp_SG_Detections_381_384_AL  # UB:Derived from original system description
    delegate SWC_PLT_Appl_Communication.Pp_SG_Detections_385_388_AL <-> outer port Pp_SG_Detections_385_388_AL  # UB:Derived from original system description
    delegate SWC_PLT_Appl_Communication.Pp_SG_Detections_389_392_AL <-> outer port Pp_SG_Detections_389_392_AL  # UB:Derived from original system description
    delegate SWC_PLT_Appl_Communication.Pp_SG_Detections_393_396_AL <-> outer port Pp_SG_Detections_393_396_AL  # UB:Derived from original system description
    delegate SWC_PLT_Appl_Communication.Pp_SG_Detections_397_400_AL <-> outer port Pp_SG_Detections_397_400_AL  # UB:Derived from original system description
    delegate SWC_PLT_Appl_Communication.Rp_SG_Fusion_Detections_001_004_AL <-> outer port Rp_SG_Fusion_Detections_001_004_AL  # UB:Derived from original system description
    delegate SWC_PLT_Appl_Communication.Rp_SG_Fusion_Detections_005_008_AL <-> outer port Rp_SG_Fusion_Detections_005_008_AL  # UB:Derived from original system description
    delegate SWC_PLT_Appl_Communication.Rp_SG_Fusion_Detections_009_012_AL <-> outer port Rp_SG_Fusion_Detections_009_012_AL  # UB:Derived from original system description
    delegate SWC_PLT_Appl_Communication.Rp_SG_Fusion_Detections_013_016_AL <-> outer port Rp_SG_Fusion_Detections_013_016_AL  # UB:Derived from original system description
    delegate SWC_PLT_Appl_Communication.Rp_SG_Fusion_Detections_017_020_AL <-> outer port Rp_SG_Fusion_Detections_017_020_AL  # UB:Derived from original system description
    delegate SWC_PLT_Appl_Communication.Rp_SG_Fusion_Detections_021_024_AL <-> outer port Rp_SG_Fusion_Detections_021_024_AL  # UB:Derived from original system description
    delegate SWC_PLT_Appl_Communication.Rp_SG_Fusion_Detections_025_028_AL <-> outer port Rp_SG_Fusion_Detections_025_028_AL  # UB:Derived from original system description
    delegate SWC_PLT_Appl_Communication.Rp_SG_Fusion_Detections_029_032_AL <-> outer port Rp_SG_Fusion_Detections_029_032_AL  # UB:Derived from original system description
    delegate SWC_PLT_Appl_Communication.Rp_SG_Fusion_Detections_033_036_AL <-> outer port Rp_SG_Fusion_Detections_033_036_AL  # UB:Derived from original system description
    delegate SWC_PLT_Appl_Communication.Rp_SG_Fusion_Detections_037_040_AL <-> outer port Rp_SG_Fusion_Detections_037_040_AL  # UB:Derived from original system description
    delegate SWC_PLT_Appl_Communication.Rp_SG_Fusion_Detections_041_044_AL <-> outer port Rp_SG_Fusion_Detections_041_044_AL  # UB:Derived from original system description
    delegate SWC_PLT_Appl_Communication.Rp_SG_Fusion_Detections_045_048_AL <-> outer port Rp_SG_Fusion_Detections_045_048_AL  # UB:Derived from original system description
    delegate SWC_PLT_Appl_Communication.Rp_SG_Fusion_Detections_049_052_AL <-> outer port Rp_SG_Fusion_Detections_049_052_AL  # UB:Derived from original system description
    delegate SWC_PLT_Appl_Communication.Rp_SG_Fusion_Detections_053_056_AL <-> outer port Rp_SG_Fusion_Detections_053_056_AL  # UB:Derived from original system description
    delegate SWC_PLT_Appl_Communication.Rp_SG_Fusion_Detections_057_060_AL <-> outer port Rp_SG_Fusion_Detections_057_060_AL  # UB:Derived from original system description
    delegate SWC_PLT_Appl_Communication.Rp_SG_Fusion_Detections_061_064_AL <-> outer port Rp_SG_Fusion_Detections_061_064_AL  # UB:Derived from original system description
    delegate SWC_PLT_Appl_Communication.Rp_SG_Fusion_Detections_065_068_AL <-> outer port Rp_SG_Fusion_Detections_065_068_AL  # UB:Derived from original system description
    delegate SWC_PLT_Appl_Communication.Rp_SG_Fusion_Detections_069_072_AL <-> outer port Rp_SG_Fusion_Detections_069_072_AL  # UB:Derived from original system description
    delegate SWC_PLT_Appl_Communication.Rp_SG_Fusion_Detections_073_076_AL <-> outer port Rp_SG_Fusion_Detections_073_076_AL  # UB:Derived from original system description
    delegate SWC_PLT_Appl_Communication.Rp_SG_Fusion_Detections_077_080_AL <-> outer port Rp_SG_Fusion_Detections_077_080_AL  # UB:Derived from original system description
    delegate SWC_PLT_Appl_Communication.Rp_SG_Fusion_Detections_081_084_AL <-> outer port Rp_SG_Fusion_Detections_081_084_AL  # UB:Derived from original system description
    delegate SWC_PLT_Appl_Communication.Rp_SG_Fusion_Detections_085_088_AL <-> outer port Rp_SG_Fusion_Detections_085_088_AL  # UB:Derived from original system description
    delegate SWC_PLT_Appl_Communication.Rp_SG_Fusion_Detections_089_092_AL <-> outer port Rp_SG_Fusion_Detections_089_092_AL  # UB:Derived from original system description
    delegate SWC_PLT_Appl_Communication.Rp_SG_Fusion_Detections_093_096_AL <-> outer port Rp_SG_Fusion_Detections_093_096_AL  # UB:Derived from original system description
    delegate SWC_PLT_Appl_Communication.Rp_SG_Fusion_Detections_097_100_AL <-> outer port Rp_SG_Fusion_Detections_097_100_AL  # UB:Derived from original system description
    delegate SWC_PLT_Appl_Communication.Rp_SG_Fusion_Detections_101_104_AL <-> outer port Rp_SG_Fusion_Detections_101_104_AL  # UB:Derived from original system description
    delegate SWC_PLT_Appl_Communication.Rp_SG_Fusion_Detections_105_108_AL <-> outer port Rp_SG_Fusion_Detections_105_108_AL  # UB:Derived from original system description
    delegate SWC_PLT_Appl_Communication.Rp_SG_Fusion_Detections_109_112_AL <-> outer port Rp_SG_Fusion_Detections_109_112_AL  # UB:Derived from original system description
    delegate SWC_PLT_Appl_Communication.Rp_SG_Fusion_Detections_113_116_AL <-> outer port Rp_SG_Fusion_Detections_113_116_AL  # UB:Derived from original system description
    delegate SWC_PLT_Appl_Communication.Rp_SG_Fusion_Detections_117_120_AL <-> outer port Rp_SG_Fusion_Detections_117_120_AL  # UB:Derived from original system description
    delegate SWC_PLT_Appl_Communication.Rp_SG_Fusion_Detections_121_124_AL <-> outer port Rp_SG_Fusion_Detections_121_124_AL  # UB:Derived from original system description
    delegate SWC_PLT_Appl_Communication.Rp_SG_Fusion_Detections_125_128_AL <-> outer port Rp_SG_Fusion_Detections_125_128_AL  # UB:Derived from original system description
    delegate SWC_PLT_Appl_Communication.Pp_SG_RadarCapability_AL <-> outer port Pp_SG_RadarCapability_AL  # UB:Derived from original system description
    delegate SWC_PLT_Appl_Communication.Pp_SG_RadarStatus2_AL <-> outer port Pp_SG_RadarStatus2_AL  # UB:Derived from original system description
    delegate SWC_PLT_Appl_Communication.Rp_SG_VehicleStatus_AL <-> outer port Rp_SG_VehicleStatus_AL  # UB:Derived from original system description
    delegate SWC_PLT_Appl_Communication.Rp_SG_XcpCTOReq_AL <-> outer port Rp_SG_XcpCTOReq_AL  # UB:Derived from original system description
    delegate SWC_PLT_Appl_Communication.Pp_SG_XcpCTOResp_AL <-> outer port Pp_SG_XcpCTOResp_AL  # UB:Derived from original system description
    delegate SWC_PLT_Appl_Communication.Pp_SG_XcpDAQResp_AL <-> outer port Pp_SG_XcpDAQResp_AL  # UB:Derived from original system description
    connect SWC_PLT_Appl_Communication.PostRadarProcessing_CAN_Tx -> SWC_PLT_CDD_Radar_Control.PostRadarProcessing_CAN_Tx  # UB:Derived from original system description
    connect SWC_PLT_Appl_IoHwAb.Pp_Vbatt_State -> SWC_PLT_Appl_Communication.Rp_Vbatt_State
    connect SWC_PLT_CDD_XCP.Pp_XCP_RFBIST_Calib_Trigger -> SWC_PLT_CDD_Radar_Control.Rp_XCP_RFBIST_Calib_Trigger  # UB:Derived from original system description
    connect SWC_PLT_CDD_FailSafe.Pp_ECC_Correctable_Fault -> SWC_PLT_Appl_NvMHandler.Rp_ECC_Correctable_Fault  # UB:Derived from original system description
    connect NvM.PS_SWC_PLT_Appl_NvMHandlerCorrectable_Fault_NvM -> SWC_PLT_Appl_NvMHandler.Rp_SWC_PLT_CDD_Correctable_Fault
    connect SWC_PLT_CDD_TimeSync.Pp_TimeSync_Status_No_Tsyn_Error -> SWC_PLT_Appl_Communication.Rp_TimeSync_Status_No_Tsyn_Error  # UB:Derived from original system description
    connect SWC_PLT_CDD_TimeSync.Pp_Time_Stamp_Delta -> SWC_PLT_Appl_Communication.Rp_Time_Stamp_Delta  # UB:Derived from original system description
    connect SWC_PLT_Appl_NvMHandler.Pp_RFE_NvM_Data -> SWC_PLT_CDD_Radar_Control.Rp_RFE_NvM_Data  # UB:Derived from original system description
    connect SWC_PLT_CDD_Radar_Control.Pp_RFE_NvM_Data -> SWC_PLT_Appl_NvMHandler.Rp_RFE_NvM_Data  # UB:Derived from original system description
    connect SWC_PLT_CDD_ExternalWdg.Pp_Pmic_Mcu_Com_Fault -> SWC_PLT_Appl_Diag.Rp_Pmic_Mcu_Com_Fault  # UB:Derived from original system description
    connect SWC_PLT_Appl_ModeManager.Pp_OperationMode_System -> SWC_PLT_Appl_Communication.Rp_OperationMode_System
    delegate SWC_PRJ_Appl_FaultMgr.Pp_ActiveFaultLatchTable <-> outer port Pp_ActiveFaultLatchTable  # UB:Derived from original system description
    delegate SWC_PRJ_Appl_FaultMgr.Pp_ActiveFaultTable <-> outer port Pp_ActiveFaultTable  # UB:Derived from original system description
    delegate SWC_PRJ_Appl_FaultMgr.Pp_FaultTestCompleteTable <-> outer port Pp_FaultTestCompleteTable  # UB:Derived from original system description
    delegate SWC_PRJ_Appl_FaultMgr.Pp_HistoryFaultTable <-> outer port Pp_HistoryFaultTable  # UB:Derived from original system description
    connect SWC_PLT_Appl_ModeManager.Pp_OperationMode_System -> SWC_PRJ_Appl_Power_Manager.Rp_OperationMode_System
    connect SWC_PRJ_Appl_Power_Manager.Pp_CustDegradation -> SWC_PLT_Appl_ModeManager.Rp_CustDegradation
    connect SWC_PRJ_Appl_Power_Manager.Pp_OpModeShutdown -> SWC_PLT_Appl_ModeManager.Rp_OpModeShutdown
    connect SWC_PLT_Appl_IoHwAb.Pp_PhysicalAdcData -> SWC_PRJ_Appl_Power_Manager.Rp_PhysicalAdcData
    connect SWC_PRJ_Appl_Power_Manager.Request_ESH_PostRunRequest_0 -> BswM.Request_ESH_PostRunRequest_0
    connect SWC_CMP_PRJ_UDSHandler.DataServices_Data_0xF190_VIN -> Dcm.DataServices_Data_VIN_Read
    connect NvM.PS_SWC_CMP_PRJ_UDSHandlerSWC_UDSHandler_VIN -> SWC_CMP_PRJ_UDSHandler.CS_NvMService_VIN
    connect Dcm.DcmEcuReset -> BswM.Notification_BswMModeRequestPort_DCMECUReset
    connect SWC_PLT_Appl_IoHwAb.Pp_Vbatt_State -> SWC_PLT_Appl_NvMHandler.Rp_Vbatt_State_Volt
    connect SWC_PLT_CDD_XCP.Pp_XCP_Program_Mode -> SWC_PLT_Appl_NvMHandler.Rp_XCP_Program_Mode
    connect SWC_CMP_PRJ_UDSHandler.Pp_SW_Version_Info -> SWC_PLT_CDD_XCP.Rp_SW_Version_Info
    connect SWC_CMP_PRJ_UDSHandler.Pp_Calibration_Version_Info -> SWC_PLT_CDD_XCP.Rp_Calibration_Version_Info
    connect SWC_CMP_PRJ_UDSHandler.Pp_Customer_SW_Version_Info -> SWC_PLT_CDD_XCP.Rp_Customer_SW_Version_Info
    connect SWC_PLT_Appl_Communication.Pp_VCAN_Srv_EnableAppTx -> SWC_PLT_CDD_XCP.Rp_VCAN_Srv_EnableAppTx
    connect SWC_PLT_Appl_Communication.Pp_VCAN_Srv_DisableAppTx -> SWC_PLT_CDD_XCP.Rp_VCAN_Srv_DisableAppTx
    connect SWC_PLT_Appl_ModeManager.Pp_OperationMode_System -> SWC_PLT_CDD_Logging.Rp_OperationModeType
    connect SWC_PLT_Appl_PlatformTime.CS_Get_Platform_Elapsed_ustime -> SWC_PLT_Radar_Alignment_Handler.CS_Get_Platform_Elapsed_ustime
    connect SWC_PLT_CDD_FailSafe.CS_Get_RepetativeReset_Faultnum -> SWC_PLT_CDD_FCRU.CS_Get_RepetativeReset_Faultnum
    connect WdgM_OsCore0_ASIL.alive_SE_Alive_Program_Flow_Monitoring -> SWC_CDD_IPC.WdgM_AliveSupervision_Alive_Program_Flow_Monitoring
    connect WdgM_OsCore0_ASIL.general_Core0 -> SWC_PLT_Appl_IntWDG.CS_WdgM_General
    connect WdgM_OsCore0_ASIL.general_Core0 -> SWC_PLT_CDD_FailSafe.CS_WdgM_General
    connect WdgM_OsCore0_ASIL.general_Core0 -> SWC_PLT_CDD_WdgHandler.CS_WdgM_General
    connect WdgM_OsCore0_ASIL.alive_SE_Internal_Wdg -> SWC_PLT_Appl_IntWDG.CS_WdgM_AliveSupervision_Internal_Wdg
    connect SWC_CMP_PRJ_UDSHandler.DataServices_Data_0x1111_ECUVoltage -> Dcm.DataServices_Data_ECUVoltage_Read
    connect SWC_CMP_PRJ_UDSHandler.DataServices_Data_0x1112_VehicleSpeed -> Dcm.DataServices_Data_VehicleSpeed_Read
    connect SWC_CMP_PRJ_UDSHandler.DataServices_Data_0x1117_Sensor_Availability_Flag -> Dcm.DataServices_Data_Sensor_Availability_Flag_Read
    connect SWC_CMP_PRJ_UDSHandler.DataServices_Data_0xA001_SoftwareNumber -> Dcm.DataServices_Data_SoftwareNumber_Read
    connect SWC_CMP_PRJ_UDSHandler.DataServices_Data_0xF15A_Software_Fingerprint -> Dcm.DataServices_Data_Software_Fingerprint_Read
    connect SWC_CMP_PRJ_UDSHandler.DataServices_Data_0xF19D_CANDBMatrixVer -> Dcm.DataServices_Data_CANDBMatrixVer_Read
    connect SWC_CMP_PRJ_UDSHandler.DataServices_Data_0xF19E_PCAN_DBC_Version -> Dcm.DataServices_Data_PCAN_DBC_Version_Read
    connect SWC_CMP_PRJ_UDSHandler.DataServices_Data_0xF18B_ECUBuildDate -> Dcm.DataServices_Data_ECUBuildDate_Read
    connect SWC_CMP_PRJ_UDSHandler.DataServices_Data_0xA004_Ego_Acceleration -> Dcm.DataServices_Data_Ego_Acceleration_Read
    connect SWC_CMP_PRJ_UDSHandler.DataServices_Data_0xF150_Hardware_Version_number -> Dcm.DataServices_Data_Hardware_Version_number_Read
    connect SWC_CMP_PRJ_UDSHandler.DataServices_Data_0xA003_SMC_Part_No_and_Revision -> Dcm.DataServices_Data_SMC_Part_No_and_Revision_Read
    connect SWC_CMP_PRJ_UDSHandler.DataServices_Data_0xA002_Dataset_Part_No_and_Revision -> Dcm.DataServices_Data_Dataset_Part_No_and_Revision_Read
    connect SWC_CMP_PRJ_UDSHandler.DataServices_Data_0xF010_Vehicle_Variant -> Dcm.DataServices_Data_Vehicle_Variant_Read
    connect SWC_CMP_PRJ_UDSHandler.DataServices_Data_0xF189_Base_Software_Version_number -> Dcm.DataServices_Data_Base_Software_Version_number_Read
    connect SWC_CMP_PRJ_UDSHandler.DataServices_Data_0xF16A_Boot_App_Identification -> Dcm.DataServices_Data_Boot_App_Identification_DID_Read
    connect SWC_CMP_PRJ_UDSHandler.DataServices_Data_0xF191_HardwareNumber -> Dcm.DataServices_Data_HardwareNumber_Read
    connect SWC_CMP_PRJ_UDSHandler.DataServices_Data_0xF186_ActiveDiagnosticSessionDataIdentifier -> Dcm.DataServices_Data_ActiveDiagnosticSessionDataIdentifier_Read
    connect SWC_CMP_PRJ_UDSHandler.DataServices_Data_0xA000_SerialNumber -> Dcm.DataServices_Data_SerialNumber_Read
    connect SWC_CMP_PRJ_UDSHandler.DataServices_Data_0xF017_Pin_Position_Status -> Dcm.DataServices_Data_Pin_Position_Status_Read
    connect SWC_CMP_PRJ_UDSHandler.DataServices_Data_0xFDA3_Read_Active_Fault_Table -> Dcm.DataServices_Data_Read_Active_Fault_Table_Read
    connect SWC_CMP_PRJ_UDSHandler.DataServices_Data_0xF180_BootloaderNumber -> Dcm.DataServices_Data_BootloaderNumber_Read
    connect SWC_CMP_PRJ_UDSHandler.DataServices_Data_0x1116_DateandTime -> Dcm.DataServices_Data_DateandTime_Read
    connect SWC_PLT_Appl_IoHwAb.Pp_PhysicalAdcData -> SWC_CMP_PRJ_UDSHandler.Rp_PhysicalAdcData
    connect SWC_PLT_Appl_ModeManager.Pp_OperationMode_System -> SWC_CMP_PRJ_UDSHandler.Rp_OperationModeType
    connect SWC_CMP_PRJ_UDSHandler.CSDataServices_Data_Snapshot_DID_0xa004_Ego_Acceleration -> DemMaster_Invalid_OsApplication.CBReadData_Data_DID_0xa004_Ego_Acceleration
    connect SWC_CMP_PRJ_UDSHandler.CSDataServices_Data_Snapshot_DID_0x1112_VehicleSpeed -> DemMaster_Invalid_OsApplication.CBReadData_Data_DID_0x1112_VehicleSpeed
    connect SWC_CMP_PRJ_UDSHandler.CSDataServices_Data_Snapshot_DID_0x1117_Sensor_Availability_Flag_Information -> DemMaster_Invalid_OsApplication.CBReadData_Data_DID_0x1117_Sensor_Availability_Flag_Information
    connect SWC_CMP_PRJ_UDSHandler.CSDataServices_Data_Snapshot_DID_0x1116_CombinedSignal -> DemMaster_Invalid_OsApplication.CBReadData_Data_DID_0x1116_CombinedSignal
    connect SWC_CMP_PRJ_UDSHandler.SecurityAccess_Unlocked_L1 -> Dcm.SecurityAccess_UnlockedL1
    connect SWC_CMP_PRJ_UDSHandler.CSDataServices_Data_Snapshot_DID_0x1111_ECUVoltage -> DemMaster_Invalid_OsApplication.CBReadData_Data_DID_0x1111_ECUVoltage
    connect SWC_CMP_PRJ_UDSHandler.ServiceRequestNotification -> Dcm.ServiceRequestSupplierNotification_DcmDslServiceRequestSupplierNotification
    connect SWC_CMP_PRJ_UDSHandler.RoutineServices_Routine_0x7005_Pin_Position_Unlock_Start -> Dcm.RoutineServices_Routine_Pin_Position_Unlock_Start
    connect SWC_CMP_PRJ_UDSHandler.RoutineServices_Routine_0x0200_CheckProgPreCond_Start -> Dcm.RoutineServices_Routine_CheckProgPreCond_Start
    connect SWC_CMP_PRJ_UDSHandler.RoutineServices_Routine_0x7004_Pin_Position_Lock_Start -> Dcm.RoutineServices_Routine_Pin_Position_Lock_Start
    connect NvM.PS_SWC_PLT_Appl_NvMHandlerSensorPos_NvM -> SWC_PLT_Appl_NvMHandler.Rp_CDD_SensorPos_UDS
    connect SWC_CMP_PRJ_UDSHandler.Pp_NvM_lock_Unclock_Status -> SWC_PLT_Appl_NvMHandler.Rp_NvM_lock_Unclock_Status
    connect SWC_PLT_Appl_NvMHandler.CS_Trigger_Write_to_NVM -> SWC_CMP_PRJ_UDSHandler.CS_NvM_Trigger_Write
    connect SWC_PLT_Appl_NvMHandler.CS_GetError_Status -> SWC_CMP_PRJ_UDSHandler.CS_GetError_Status
    connect SWC_PLT_Appl_NvMHandler.CS_ReadNvM_Value -> SWC_CMP_PRJ_UDSHandler.CS_ReadNvM_Value
    connect SWC_PRJ_Appl_SensorPosition.Pp_PinPosition_Mismatch_Fault_Status -> SWC_PRJ_Appl_FaultMgr.Rp_PinPosition_Mismatch_Fault_Status
    connect DemSatellite_Invalid_OsApplication.Event_Radar_Mounting_Orientation_Incorrect_Assembly -> SWC_PRJ_Appl_FaultMgr.FaultMgr_DiagnosticMonitor_RADAR_Mounting_Orientation_Incorrect_Assembly_Fault
    connect DemSatellite_Invalid_OsApplication.Event_Radar_AutoAlignment_Range_Alignment_or_Adjustement_Incorrect -> SWC_PRJ_Appl_FaultMgr.FaultMgr_DiagnosticMonitor_RADAR_AutoAlignment_Range_Alignment_or_Adjustment_Incorrect_Fault
    connect DemSatellite_Invalid_OsApplication.Event_PCAN_TimeSync_Missing_Message -> SWC_PRJ_Appl_FaultMgr.FaultMgr_DiagnosticMonitor_RADAR_Time_Synchronization_Fault
    connect DemSatellite_Invalid_OsApplication.Event_Radar_MMIC_Component_Failure -> SWC_PRJ_Appl_FaultMgr.FaultMgr_DiagnosticMonitor_RADAR_Application_Radar_MMIC_Component_Internal_Failure_Fault
    connect DemSatellite_Invalid_OsApplication.Event_Radar_AutoAlignment_Misalignment_Performance_or_Incorrect_Operation -> SWC_PRJ_Appl_FaultMgr.FaultMgr_DiagnosticMonitor_RADAR_AutoAlignment_Misalignment_Performance_or_Incorrect_Fault
    connect DemSatellite_Invalid_OsApplication.Event_Radar_MMIC_RFBIST_Component_Internal_Failure -> SWC_PRJ_Appl_FaultMgr.FaultMgr_DiagnosticMonitor_RADAR_MMIC_RFBIST_Component_or_System_Internal_Failure_Fault
    connect DemSatellite_Invalid_OsApplication.Event_Radar_Module_Watchdog_Failure -> SWC_PRJ_Appl_FaultMgr.FaultMgr_DiagnosticMonitor_RADAR_Module_Watchdog_or_Safety_Failure_Fault
    connect DemSatellite_Invalid_OsApplication.Event_Radar_AutoAlignment_Algorithm_Signal_Calculation_Failure -> SWC_PRJ_Appl_FaultMgr.FaultMgr_DiagnosticMonitor_RADAR_AutoAlignment_Algorithm_Signal_Calculation_Failure_Fault
    connect DemSatellite_Invalid_OsApplication.Event_Application_Interface_Lookup_Performance_or_Incorrect_Operation -> SWC_PRJ_Appl_FaultMgr.FaultMgr_DiagnosticMonitor_RADAR_Application_Interface_Lookup_Performance_OR_incorrect_Fault
    connect DemSatellite_Invalid_OsApplication.Event_Radar_SMC_General_Checksum_Failure -> SWC_PRJ_Appl_FaultMgr.FaultMgr_DiagnosticMonitor_RADAR_SMC_General_Checksum_Failure_Fault
    connect DemSatellite_Invalid_OsApplication.Event_Radar_Platform_Time_System_Programming_Failure -> SWC_PRJ_Appl_FaultMgr.FaultMgr_DiagnosticMonitor_RADAR_Platform_Time_Sync_error_Fault
    connect DemSatellite_Invalid_OsApplication.Event_Radar_Initial_Alignment_Missing_Calibration -> SWC_PRJ_Appl_FaultMgr.FaultMgr_DiagnosticMonitor_RADAR_Initial_Alignment_Missing_Calibration_Fault
    connect DemSatellite_Invalid_OsApplication.Event_Radar_Module_General_Memory_Failure -> SWC_PRJ_Appl_FaultMgr.FaultMgr_DiagnosticMonitor_RADAR_Module_General_Memory_Failure_Fault
    connect DemSatellite_Invalid_OsApplication.Event_Radar_Module_System_Internal_Failure -> SWC_PRJ_Appl_FaultMgr.FaultMgr_DiagnosticMonitor_RADAR_Module_System_Internal_Failure_Fault
    connect DemSatellite_Invalid_OsApplication.Event_Radar_Module_Over_Temperature -> SWC_PRJ_Appl_FaultMgr.FaultMgr_DiagnosticMonitor_RADAR_Module_Over_Temperature_Fault
    connect DemSatellite_Invalid_OsApplication.Event_Radar_calibration_Calibration_or_Paramater_Memory_Failure -> SWC_PRJ_Appl_FaultMgr.FaultMgr_DiagnosticMonitor_RADAR_Calibration_or_Parameter_Memory_Fault
    connect DemSatellite_Invalid_OsApplication.Event_Radar_Performance_Capability_Algorithm_Based_Failure -> SWC_PRJ_Appl_FaultMgr.FaultMgr_DiagnosticMonitor_RADAR_Performance_Capability_Algorithm_Based_Failure_Fault
    delegate SWC_PLT_Appl_Communication.Pp_RDR_Radar_SW_Info <-> outer port PP_RDR_Radar_SW_Info  # UB:Derived from original system description
    delegate SWC_PLT_Appl_Communication.Pp_RDR_Radar_Status <-> outer port PP_RDR_Radar_Status  # UB:Derived from original system description
    delegate SWC_PLT_Appl_Communication.Pp_RDR_DetectionList_Event <-> outer port PP_DetectionList_Event  # UB:Derived from original system description
    delegate SWC_PLT_Appl_Communication.RP_RDR_Vehicle_Status <-> outer port RP_Vehicle_Status  # UB:Derived from original system description
    delegate SWC_PLT_Appl_Communication.Rp_SG_ADAS_FN_Enable_disable_sts_ALVCAN <-> outer port Rp_SG_ADAS_FN_Enable_disable_sts_ALVCAN  # UB:Derived from original system description
    delegate SWC_PLT_Appl_Communication.Rp_SG_CCVS1_ALVCAN <-> outer port Rp_SG_CCVS1_ALVCAN  # UB:Derived from original system description
    delegate SWC_PLT_Appl_Communication.Rp_SG_CLS_Tx_16_ALVCAN <-> outer port Rp_SG_CLS_Tx_16_ALVCAN  # UB:Derived from original system description
    delegate SWC_PLT_Appl_Communication.Rp_SG_CLS_Tx_4_ALVCAN <-> outer port Rp_SG_CLS_Tx_4_ALVCAN  # UB:Derived from original system description
    delegate SWC_PLT_Appl_Communication.Rp_SG_ETC2_00_ALVCAN <-> outer port Rp_SG_ETC2_00_ALVCAN  # UB:Derived from original system description
    delegate SWC_PLT_Appl_Communication.Rp_SG_ETC2_03_ALVCAN <-> outer port Rp_SG_ETC2_03_ALVCAN  # UB:Derived from original system description
    delegate SWC_PLT_Appl_Communication.Rp_SG_OEL_ALVCAN <-> outer port Rp_SG_OEL_ALVCAN  # UB:Derived from original system description
    delegate SWC_PLT_Appl_Communication.Rp_SG_SAS_ALVCAN <-> outer port Rp_SG_SAS_ALVCAN  # UB:Derived from original system description
    delegate SWC_PLT_Appl_Communication.Rp_SG_TD_ALVCAN <-> outer port Rp_SG_TD_ALVCAN  # UB:Derived from original system description
    delegate SWC_PLT_Appl_Communication.Rp_SG_VD_ALVCAN <-> outer port Rp_SG_VD_ALVCAN  # UB:Derived from original system description
    delegate SWC_PLT_Appl_Communication.Rp_SG_VDC2_ALVCAN <-> outer port Rp_SG_VDC2_ALVCAN  # UB:Derived from original system description
    delegate SWC_PLT_Appl_Communication.Rp_SG_VI_ALVCAN <-> outer port Rp_SG_VI_ALVCAN  # UB:Derived from original system description
    delegate SWC_PLT_Appl_Communication.Rp_SG_Fusion_AlignmentStatus1_ALPCAN <-> outer port Rp_SG_Fusion_AlignmentStatus1_ALPCAN  # UB:Derived from original system description
    delegate SWC_PLT_Appl_Communication.Rp_SG_Fusion_AlignmentStatus2_ALPCAN <-> outer port Rp_SG_Fusion_AlignmentStatus2_ALPCAN  # UB:Derived from original system description
    delegate SWC_PLT_Appl_Communication.Rp_SG_Fusion_RadarCapability_ALPCAN <-> outer port Rp_SG_Fusion_RadarCapability_ALPCAN  # UB:Derived from original system description
    delegate SWC_PLT_Appl_Communication.Rp_SG_Fusion_RadarStatus2_ALPCAN <-> outer port Rp_SG_Fusion_RadarStatus2_ALPCAN  # UB:Derived from original system description
    delegate SWC_PLT_Appl_Communication.Rp_SG_GW_ADAS_FN_Enable_disable_sts_ALPCAN <-> outer port Rp_SG_GW_ADAS_FN_Enable_disable_sts_ALPCAN  # UB:Derived from original system description
    delegate SWC_PLT_Appl_Communication.Rp_SG_GW_CCVS1_ALPCAN <-> outer port Rp_SG_GW_CCVS1_ALPCAN  # UB:Derived from original system description
    delegate SWC_PLT_Appl_Communication.Rp_SG_GW_CLS_Tx_16_ALPCAN <-> outer port Rp_SG_GW_CLS_Tx_16_ALPCAN  # UB:Derived from original system description
    delegate SWC_PLT_Appl_Communication.Rp_SG_GW_CLS_Tx_4_ALPCAN <-> outer port Rp_SG_GW_CLS_Tx_4_ALPCAN  # UB:Derived from original system description
    delegate SWC_PLT_Appl_Communication.Rp_SG_GW_ETC2_ALPCAN <-> outer port Rp_SG_GW_ETC2_ALPCAN  # UB:Derived from original system description
    delegate SWC_PLT_Appl_Communication.Rp_SG_GW_OEL_ALPCAN <-> outer port Rp_SG_GW_OEL_ALPCAN  # UB:Derived from original system description
    delegate SWC_PLT_Appl_Communication.Rp_SG_GW_SAS_ALPCAN <-> outer port Rp_SG_GW_SAS_ALPCAN  # UB:Derived from original system description
    delegate SWC_PLT_Appl_Communication.Rp_SG_GW_TD_ALPCAN <-> outer port Rp_SG_GW_TD_ALPCAN  # UB:Derived from original system description
    delegate SWC_PLT_Appl_Communication.Rp_SG_GW_VD_ALPCAN <-> outer port Rp_SG_GW_VD_ALPCAN  # UB:Derived from original system description
    delegate SWC_PLT_Appl_Communication.Rp_SG_GW_VI_ALPCAN <-> outer port Rp_SG_GW_VI_ALPCAN  # UB:Derived from original system description
    delegate SWC_PLT_Appl_Communication.Rp_SG_GW_ETC2_03_ALPCAN <-> outer port Rp_SG_GW_ETC2_03_ALPCAN  # UB:Derived from original system description
    delegate SWC_PLT_Appl_Communication.Rp_SG_GW_VDC2_ALPCAN <-> outer port Rp_SG_GW_VDC2_ALPCAN  # UB:Derived from original system description
    delegate SWC_PLT_Appl_Communication.Pp_SG_GW_prop_ADAS_BSIS_info_ALPCAN <-> outer port Pp_SG_GW_prop_ADAS_BSIS_info_ALPCAN  # UB:Derived from original system description
    delegate SWC_PLT_Appl_Communication.Pp_SG_RDR_BSD1_Tx_ALPCAN <-> outer port Pp_SG_RDR_BSD1_Tx_ALPCAN  # UB:Derived from original system description
    delegate SWC_PLT_Appl_Communication.Pp_SG_MOIS_ALVCAN <-> outer port Pp_SG_MOIS_ALVCAN  # UB:Derived from original system description
    delegate SWC_PLT_Appl_Communication.Pp_SG_prop_ADAS_MOIS_info_ALVCAN <-> outer port Pp_SG_prop_ADAS_MOIS_info_ALVCAN  # UB:Derived from original system description
    delegate SWC_PLT_Appl_Communication.Rp_SG_Fusion_RadarHeader_ALPCAN <-> outer port Rp_SG_Fusion_RadarHeader_ALPCAN  # UB:Derived from original system description
    delegate SWC_PLT_Appl_Communication.Rp_SG_Fusion_RadarStatus_ALPCAN <-> outer port Rp_SG_Fusion_RadarStatus_ALPCAN  # UB:Derived from original system description
    delegate SWC_PLT_Appl_Communication.Pp_SG_RadarHeader_ALPCAN <-> outer port Pp_SG_RadarHeader_ALPCAN  # UB:Derived from original system description
    delegate SWC_PLT_Appl_Communication.Pp_SG_RadarStatus1_ALPCAN <-> outer port Pp_SG_RadarStatus1_ALPCAN  # UB:Derived from original system description
    connect SWC_PLT_Appl_PlatformTime.Get_PlatfromTime_us -> SWC_PLT_Radar_Alignment_Handler.CS_Get_PlatfromTime_us
    connect SWC_PLT_Radar_Alignment_Handler.Pp_AlignmentStatic -> SWC_PLT_Appl_Communication.Rp_AlignmentStatic
    connect SWC_PLT_Radar_Alignment_Handler.Pp_Alignment_Handler -> SWC_PLT_Appl_Communication.Rp_Alignment_Handler
    connect SWC_PLT_Radar_Alignment_Handler.Pp_Alignment_M2D_Data -> SWC_PLT_Appl_Communication.Rp_Alignment_M2D_Data
    connect SWC_PLT_Radar_Alignment_Handler.Pp_AlignmentShortTrack -> SWC_PLT_Appl_Communication.Rp_AlignmentShortTrack
    connect SWC_PLT_Radar_Alignment_Handler.Pp_AlignmentService -> SWC_PLT_Appl_Communication.Rp_AlignmentService
    connect SWC_PLT_Radar_Alignment_Handler.Pp_AlignmentAuto -> SWC_PLT_Appl_Communication.Rp_AlignmentAuto
    connect SWC_CMP_PRJ_UDSHandler.CSCallbackDTCStatusChange -> DemMaster_Invalid_OsApplication.CBStatusDTC_DemCallbackDTCStatusChanged
    connect SWC_PLT_Appl_Communication.Pp_CCVS1_message_Vcan_Safety_Timeout_Status -> SWC_PRJ_Appl_FaultMgr.Rp_CCVS1_message_Vcan_Safety_Timeout_Status
    connect SWC_PLT_Appl_Communication.Pp_Header_msg_Com_Rx_Timeout_Status -> SWC_PRJ_Appl_FaultMgr.Rp_Header_msg_Com_Rx_Timeout_Status
    connect SWC_PLT_Appl_Communication.Pp_OEL_message_Non_Safety_Timeout_Status -> SWC_PRJ_Appl_FaultMgr.Rp_OEL_message_Non_Safety_Timeout_Status
    connect SWC_PLT_Appl_Communication.Pp_ETC2_AT_AMT_message_Vcan_Safety_Timeout_Status -> SWC_PRJ_Appl_FaultMgr.Rp_ETC2_AT_AMT_message_Vcan_Safety_Timeout_Status
    connect SWC_PLT_Appl_Communication.Pp_Radar_Status_2_Com_Rx_Timeout_Status -> SWC_PRJ_Appl_FaultMgr.Rp_Radar_Status_2_Com_Rx_Timeout_Status
    connect SWC_PLT_Appl_Communication.Pp_VDC2_message_Vcan_Safety_Timeout_Status -> SWC_PRJ_Appl_FaultMgr.Rp_VDC2_message_Vcan_Safety_Timeout_Status
    connect SWC_PLT_Appl_Communication.Pp_ETC2_MT_Variant_message_Vcan_Safety_Timeout_Status -> SWC_PRJ_Appl_FaultMgr.Rp_ETC2_MT_Variant_message_Vcan_Safety_Timeout_Status
    connect SWC_PLT_Appl_Communication.Pp_Radar_Capability_Com_Rx_Timeout_Status -> SWC_PRJ_Appl_FaultMgr.Rp_Radar_Capability_Com_Rx_Timeout_Status
    connect SWC_PLT_Appl_Communication.Pp_Radar_Status_1_Com_Rx_Timeout_Status -> SWC_PRJ_Appl_FaultMgr.Rp_Radar_Status_1_Com_Rx_Timeout_Status
    connect SWC_PLT_Appl_Communication.Pp_Alignment_Status_1_Com_Rx_Timeout_Status -> SWC_PRJ_Appl_FaultMgr.Rp_Alignment_Status_1_Com_Rx_Timeout_Status
    connect SWC_PLT_Appl_Communication.Pp_SAS_message_Non_Safety_Timeout_Status -> SWC_PRJ_Appl_FaultMgr.Rp_SAS_message_Non_Safety_Timeout_Status
    connect SWC_PLT_Appl_Communication.Pp_ADAS_Function_Switch_message_Non_Safety_Timeout_Status -> SWC_PRJ_Appl_FaultMgr.Rp_ADAS_Function_Switch_message_Non_Safety_Timeout_Status
    connect SWC_PLT_Appl_Communication.Pp_TD_message_Non_Safety_Timeout_Status -> SWC_PRJ_Appl_FaultMgr.Rp_TD_message_Non_Safety_Timeout_Status
    connect DemSatellite_Invalid_OsApplication.Event_Front_Left_Side_Radar_Missing_Message -> SWC_PRJ_Appl_FaultMgr.FaultMgr_DiagnosticMonitor_RADAR_Front_Left_Side_Radar_Missing_Message_Fault
    connect SWC_PLT_Appl_Communication.Pp_CLS_TX_16_message_Non_Safety_Timeout_Status -> SWC_PRJ_Appl_FaultMgr.Rp_CLS_TX_16_message_Non_Safety_Timeout_Status
    connect SWC_PLT_Appl_Communication.Pp_VD_message_Non_Safety_Timeout_Status -> SWC_PRJ_Appl_FaultMgr.Rp_VD_message_Non_Safety_Timeout_Status
    connect SWC_PLT_Appl_Communication.Pp_CLS_TX_4_message_Non_Safety_Timeout_Status -> SWC_PRJ_Appl_FaultMgr.Rp_CLS_TX_4_message_Non_Safety_Timeout_Status
    connect DemSatellite_Invalid_OsApplication.Event_ESC_ECU_VDC2_message_Missing_Message -> SWC_PRJ_Appl_FaultMgr.FaultMgr_DiagnosticMonitor_RADAR_ESC_ECU_VDC2_message_Missing_Message_Fault
    connect DemSatellite_Invalid_OsApplication.Event_EMS_ECU_ETC2_00_message_Missing_Message -> SWC_PRJ_Appl_FaultMgr.FaultMgr_DiagnosticMonitor_RADAR_EMS_ECU_ETC2_00_message_Missing_Message_Fault
    connect DemSatellite_Invalid_OsApplication.Event_Cluster_ECU_OEL_message_Missing_Message -> SWC_PRJ_Appl_FaultMgr.FaultMgr_DiagnosticMonitor_RADAR_Cluster_ECU_OEL_message_Missing_Fault
    connect DemSatellite_Invalid_OsApplication.Event_Cluster_ECU_CLS_Tx_16_message_Missing_Message -> SWC_PRJ_Appl_FaultMgr.FaultMgr_DiagnosticMonitor_RADAR_Cluster_ECU_CLS_Tx_16_message_Missing_Message_Fault
    connect DemSatellite_Invalid_OsApplication.Event_Cluster_ECU_TD_message_Missing_Message -> SWC_PRJ_Appl_FaultMgr.FaultMgr_DiagnosticMonitor_RADAR_Cluster_ECU_TD_message_Missing_Message_Fault
    connect DemSatellite_Invalid_OsApplication.Event_EMS_ECU_VD_message_Missing_Message -> SWC_PRJ_Appl_FaultMgr.FaultMgr_DiagnosticMonitor_RADAR_EMS_ECU_VD_message_Missing_Message_Fault
    connect DemSatellite_Invalid_OsApplication.Event_SAS_ECU_SAS_message_Missing_Message -> SWC_PRJ_Appl_FaultMgr.FaultMgr_DiagnosticMonitor_RADAR_SAS_ECU_SAS_message_Missing_Message_Fault
    connect DemSatellite_Invalid_OsApplication.Event_Cluster_ECU_ADAS_FN_STS_message_Missing_Message -> SWC_PRJ_Appl_FaultMgr.FaultMgr_DiagnosticMonitor_RADAR_Cluster_ECU_ADAS_FN_STS_message_Missing_Message_Fault
    connect DemSatellite_Invalid_OsApplication.Event_EMS_ECU_CCVS1_message_Missing_Message -> SWC_PRJ_Appl_FaultMgr.FaultMgr_DiagnosticMonitor_RADAR_EMS_ECU_CCVS1_message_Missing_Message_Fault
    connect DemSatellite_Invalid_OsApplication.Event_AT_AMT_ECU_ETC2_03_message_Missing_Message -> SWC_PRJ_Appl_FaultMgr.FaultMgr_DiagnosticMonitor_RADAR_AT_or_AMT_ECU_ETC2_03_message_Missing_Message_Fault
    connect DemSatellite_Invalid_OsApplication.Event_Cluster_ECU_CLS_Tx_4_message_Missing_Message -> SWC_PRJ_Appl_FaultMgr.FaultMgr_DiagnosticMonitor_RADAR_Cluster_ECU_CLS_Tx_4_message_Missing_Message_Fault
    connect SWC_CMP_PRJ_UDSHandler.Pp_Security_Access_Ath_Fault -> SWC_PRJ_Appl_FaultMgr.Rp_Security_Access_Ath_Fault
    connect SWC_PLT_Appl_NvMHandler.Pp_Sensor_NvM_Corruption_Fault -> SWC_PRJ_Appl_FaultMgr.Rp_Sensor_NvM_Corruption_Fault
    connect SWC_PRJ_Appl_Security_Manager.CS_HSE_Security_Compare_key -> SWC_CMP_PRJ_UDSHandler.CS_HSE_Security_Compare_key
    connect SWC_PRJ_Appl_Security_Manager.CS_HSE_Security_generate_seed -> SWC_CMP_PRJ_UDSHandler.CS_HSE_Security_generate_seed
    connect SWC_PLT_Appl_NvMHandler.CS_ReadNvM_Value -> SWC_PRJ_Appl_SensorPosition.CS_Sensorpos_ReadNvM_Value
    connect SWC_PRJ_Appl_SensorPosition.CS_Get_Pinposition_Status -> SWC_CMP_PRJ_UDSHandler.CS_Get_Pinposition_Status
    connect SWC_PLT_Appl_PlatformTime.CS_Get_Platform_Elapsed_ustime -> SWC_CMP_PRJ_UDSHandler.CS_UDS_Get_Platform_Elapsed_ustime
    connect SWC_PLT_Appl_PlatformTime.Get_PlatfromTime_us -> SWC_CMP_PRJ_UDSHandler.CS_UDS_Get_PlatfromTime_us
    connect SWC_PLT_Appl_FaultMgr.Pp_Platform_FaultTestComplete_Table -> SWC_CMP_PRJ_UDSHandler.Rp_Platform_FaultTestComplete_Table
    connect SWC_PLT_Appl_Communication.Pp_SG_VehicleStatus_AL -> SWC_CMP_PRJ_UDSHandler.Rp_SG_VehicleStatus_AL
    connect Dcm.DCMServices -> SWC_CMP_PRJ_UDSHandler.DCMServices
    connect NvM.PS_SWC_CMP_PRJ_UDSHandlerSWC_UDSHandler_Attemptcounter -> SWC_CMP_PRJ_UDSHandler.CS_NvMService_AttemptCounter
    connect NvM.PS_SWC_PLT_Appl_NvMHandlerSWC_Manual_alignment_Execution -> SWC_PLT_Appl_NvMHandler.CS_NvMService_ManualAlignment
    connect SWC_PLT_Radar_Alignment_Handler.Pp_Service_Alignment_Engineering_Non_Configuration_Parameters -> SWC_CMP_PRJ_UDSHandler.Rp_Service_Alignment_Engineering_Non_Configuration_Parameters
    connect SWC_PLT_Radar_Alignment_Handler.Pp_Manual_Alignment_Execution_Read_From_Alignment_Data_CRC -> SWC_CMP_PRJ_UDSHandler.Rp_Manual_Alignment_Execution_Read_From_Alignment_Data_CRC
    connect SWC_CMP_PRJ_UDSHandler.Pp_Manual_Alignment_Execution_Data_From_UDS_CRC -> SWC_PLT_Radar_Alignment_Handler.Rp_Manual_Alignment_Execution_Data_From_UDS_CRC
    connect SWC_PLT_Radar_Alignment_Handler.Pp_Service_Alignment_Result_Parameters -> SWC_CMP_PRJ_UDSHandler.Rp_Service_Alignment_Result_Parameters
    connect SWC_PLT_Radar_Alignment_Handler.Pp_Static_Alignment_Engineering_Parameters -> SWC_CMP_PRJ_UDSHandler.Rp_Static_Alignment_Engineering_Parameters
    connect SWC_CMP_PRJ_UDSHandler.Pp_Static_Alignment_Engineering_Write_Configuration_Parameters_CRC -> SWC_PLT_Radar_Alignment_Handler.Rp_Static_Alignment_Engineering_Write_Configuration_Parameters_CRC
    connect SWC_PRJ_Appl_FaultMgr.CS_Control_DTC_Service -> SWC_CMP_PRJ_UDSHandler.CS_Control_DTC_Service
    connect SWC_PLT_Radar_Alignment_Handler.Pp_Auto_Alignment_Status_Information -> SWC_CMP_PRJ_UDSHandler.Rp_Auto_Alignment_Status_Information
    connect SWC_PLT_Radar_Alignment_Handler.Pp_StaticAlignment_NonConfig_Param -> SWC_CMP_PRJ_UDSHandler.Rp_StaticAlignment_NonConfig_Param
    connect SWC_PLT_CDD_TimeSync.Pp_Time_Synchronization_Fault_Status -> SWC_PRJ_Appl_FaultMgr.Rp_Time_Synchronization_Fault_Status
    connect SWC_PRJ_Appl_Security_Manager.Pp_Crypto_customfuntions_version -> SWC_PLT_CDD_Logging.Rp_Crypto_customfuntions_version
    connect StbM.GlobalTime_Slave_StbMSynchronizedTimeBase_CanTsync -> SWC_PLT_CDD_TimeSync.Pp_GlobalTime_Slave_StbMSynchronizedTimeBase_CanTsync
    connect DemSatellite_Invalid_OsApplication.Event_ECU_NVM_Corruption_Program_memory_Failure -> SWC_PRJ_Appl_FaultMgr.FaultMgr_DiagnosticMonitor_RADAR_NVM_Corruption_Program_Memory_Failure_Fault
    connect DemSatellite_Invalid_OsApplication.Event_Exceeded_Security_Access_0x27_Attempt_Threshold_Authentication_Failure -> SWC_PRJ_Appl_FaultMgr.FaultMgr_DiagnosticMonitor_RADAR_Security_Access_0x27_Attempt_Threshold_Authentication_Failure_Fault
    connect DemSatellite_Invalid_OsApplication.Event_Radar_Pin_Position_Wrong_Mounting_Position -> SWC_PRJ_Appl_FaultMgr.FaultMgr_DiagnosticMonitor_RADAR_Radar_Pin_Position_Wrong_Mounting_Position_Fault
    connect DemSatellite_Invalid_OsApplication.Event_Vehicle_Dataset_value_of_signal_protection_calculation_Incorrect -> SWC_PRJ_Appl_FaultMgr.FaultMgr_DiagnosticMonitor_RADAR_Vehicle_Dataset_Value_of_Signal_Protection_Calculation_Incorrect_Fault
    connect DemSatellite_Invalid_OsApplication.Event_Vehicle_DataSet_Not_Configured -> SWC_PRJ_Appl_FaultMgr.FaultMgr_DiagnosticMonitor_RADAR_Vehicle_DatasetNot_Configured_Fault
    connect SWC_CMP_PRJ_UDSHandler.RoutineServices_Routine_0x7003_Service_Alignment_Execution_Start -> Dcm.RoutineServices_Routine_Service_Alignment_Execution_Start
    connect SWC_CMP_PRJ_UDSHandler.DataServices_Data_0xF011_Static_Alignment_Engineering_Non_Configuration_Parameters -> Dcm.DataServices_Data_Static_Alignment_Engineering_Non_Configuration_Parameters_Read
    connect SWC_CMP_PRJ_UDSHandler.DataServices_Data_0xF01C_Static_Alignment_Result_Parameters -> Dcm.DataServices_Data_Static_Alignment_Result_Parameters_Read
    connect SWC_CMP_PRJ_UDSHandler.DataServices_Data_0xF01B_Manual_Alignment_Execution -> Dcm.DataServices_Data_Manual_Alignment_Execution_Read
    connect SWC_CMP_PRJ_UDSHandler.DataServices_Data_0xF016_Auto_Alignment_Status_Information -> Dcm.DataServices_Data_Auto_Alignment_Status_Information_Read
    connect SWC_CMP_PRJ_UDSHandler.RoutineServices_Routine_0x7000_Static_Alignment_Execution_Start -> Dcm.RoutineServices_Routine_Static_Alignment_Execution_Start
    connect SWC_CMP_PRJ_UDSHandler.DataServices_Data_0xF012_Static_Alignment_Engineering_Read_Parameters -> Dcm.DataServices_Data_Static_Alignment_Engineering_Read_Parameters_Read
    connect SWC_CMP_PRJ_UDSHandler.DataServices_Data_0xF015_Service_Alignment_Result_Parameters -> Dcm.DataServices_Data_Service_Alignment_Result_Parameters_Read
    connect SWC_CMP_PRJ_UDSHandler.DataServices_Data_0xF014_Service_Alignment_Engineering_Non_Configuration_Parameters -> Dcm.DataServices_Data_Service_Alignment_Engineering_Non_Configuration_Parameters_Read
    connect SWC_CMP_PRJ_UDSHandler.DataServices_Data_0xF013_Static_Alignment_Engineering_Write_Configuration_Parameter -> Dcm.DataServices_Data_Static_Alignment_Engineering_Write_Configuration_Parameter_Write
    connect SWC_CDD_IPC.Pp_VSE_NVM_Params -> SWC_PLT_Appl_NvMHandler.Rp_VSE_NVM_Params
    connect NvM.PS_SWC_PLT_Appl_NvMHandlerSWC_Static_Alignment_Write_Parameters -> SWC_PLT_Appl_NvMHandler.CS_NvMService_Static_Alignment_Engineering_Write_Configuration_Parameters
    connect NvM.PS_SWC_PLT_Appl_NvMHandlerSWC_VSE_NVM_Params -> SWC_PLT_Appl_NvMHandler.CS_NvMService_VSE_Parameters
    connect DemSatellite_Invalid_OsApplication.Event_PCAN_Communication_Bus_Off -> SWC_PRJ_Appl_FaultMgr.FaultMgr_DiagnosticMonitor_RADAR_PCAN_Communication_Bus_off_Fault
    connect DemSatellite_Invalid_OsApplication.Event_VCAN_Communication_Bus_Off -> SWC_PRJ_Appl_FaultMgr.FaultMgr_DiagnosticMonitor_RADAR_VCAN_Communication_Bus_off_Fault
    connect SWC_PLT_Appl_IoHwAb.Pp_Vbatt_State -> SWC_PRJ_Appl_FaultMgr.Rp_FaultMngr_Vbatt_State
    connect DemSatellite_Invalid_OsApplication.Event_Radar_System_Battery_High_Voltage_System_Voltage_High -> SWC_PRJ_Appl_FaultMgr.FaultMgr_DiagnosticMonitor_RADAR_Battery_Voltage_System_Voltage_High_Fault
    connect DemSatellite_Invalid_OsApplication.Event_Radar_System_Battery_Low_Voltage_System_Voltage_Low -> SWC_PRJ_Appl_FaultMgr.FaultMgr_DiagnosticMonitor_RADAR_Battery_Voltage_System_Voltage_Low_Fault
    connect WdgM_OsCore0_ASIL.alive_SE_Internal_Wdg_BSW_Task -> SWC_PLT_Appl_IntWDG.CS_WdgM_AliveSupervision_Internal_Wdg_BSW_Task
    connect WdgM_OsCore0_ASIL.alive_SE_Internal_Wdg_PLT_Appl_Task -> SWC_PLT_Appl_IntWDG.CS_WdgM_AliveSupervision_Internal_Wdg_PLT_Appl_Task
    connect WdgM_OsCore0_ASIL.alive_SE_Internal_Wdg_Appl_IPC_Task -> SWC_PLT_Appl_IntWDG.CS_WdgM_AliveSupervision_Internal_Wdg_Appl_IPC_Task
    connect WdgM_OsCore0_ASIL.alive_SE_Internal_Wdg_Appl_Task_Radar_Control -> SWC_PLT_Appl_IntWDG.CS_WdgM_AliveSupervision_Internal_Wdg_Appl_Task_Radar_Control
    connect WdgM_OsCore0_ASIL.alive_SE_Internal_Wdg_Appl_Task_Communication -> SWC_PLT_Appl_IntWDG.CS_WdgM_AliveSupervision_Internal_Wdg_Appl_Task_Communication
    connect SWC_PLT_Appl_Communication.Pp_Pcan_Communication_ETE_fault -> SWC_PRJ_Appl_FaultMgr.Rp_Pcan_Communication_ETE_fault
    connect DemSatellite_Invalid_OsApplication.Event_Front_Left_Side_Radar_value_of_signal_protection_calculation_Incorrect -> SWC_PRJ_Appl_FaultMgr.FaultMgr_DiagnosticMonitor_RADAR_Front_Left_Side_Radar_Value_of_Signal_Protection_Calculation_Incorrect_Fault
    connect SWC_CMP_PRJ_UDSHandler.Pp_Static_Alignment_Engineering_Write_Configuration_Parameters_NVM_CRC -> SWC_PLT_Appl_NvMHandler.Rp_Static_Alignment_Engineering_Write_Configuration_Parameters_CRC
    connect SWC_PLT_Appl_NvMHandler.Pp_Static_Alignment_Engineering_Write_Configuration_Parameters_CRC -> SWC_CMP_PRJ_UDSHandler.Rp_Static_Alignment_Engineering_Write_Configuration_Parameters_NVM_CRC
    connect SWC_CMP_PRJ_UDSHandler.Pp_Manual_Alignment_Execution_Data_NVM_CRC -> SWC_PLT_Appl_NvMHandler.Rp_Manual_Alignment_Execution_Data_CRC
    connect SWC_PLT_Appl_NvMHandler.Pp_Manual_Alignment_Execution_Data_CRC -> SWC_CMP_PRJ_UDSHandler.RP_Manual_Alignment_Execution_Data_NVM_CRC
    connect SWC_PLT_Radar_Alignment_Handler.Pp_Alignment_M2D_Data -> SWC_PLT_CDD_Logging.Rp_Alignment_M2D_Data
  end to end protection set E2EPROTECTIONSET
  port interface mapping set PORTINTERFACEMAPPINGSET
  client id definition set CLIENT_ID_DEFINITION_SET
